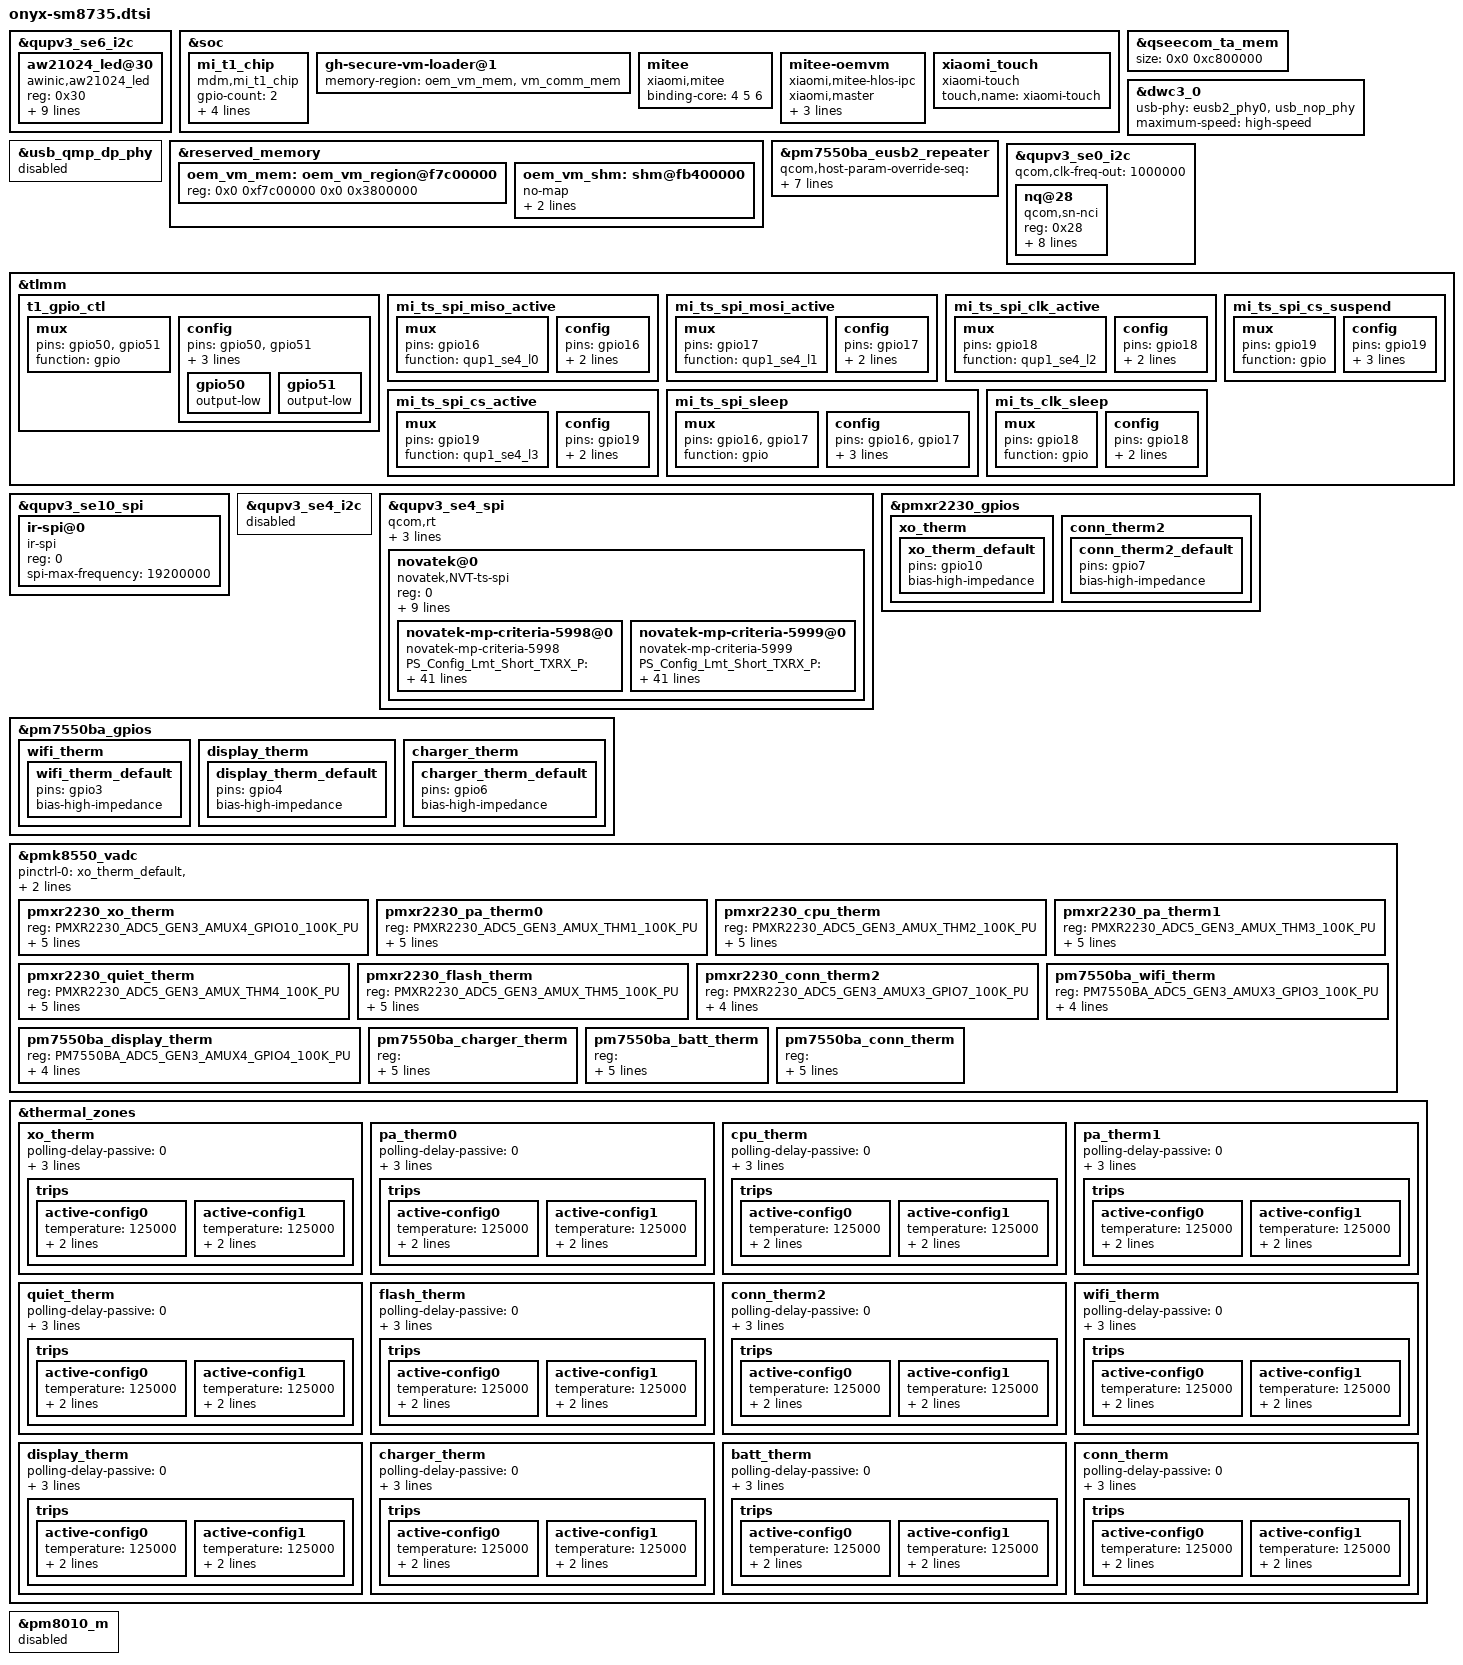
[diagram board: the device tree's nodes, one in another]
/*
  this file is for attribution only of onyx
  And public attribution of xiaomi platforms（like O10U and so on)
*/

#include "onyx-pinctrl.dtsi"
#include "sm8735-xiaomi-common.dtsi"
#include "onyx-charger-common.dtsi"
#include "onyx-sm8735-xiaomi-fingerprint.dtsi"
#include <dt-bindings/iio/qcom,spmi-adc5-gen3-pm7550ba.h>
#include <dt-bindings/iio/qcom,spmi-adc5-gen3-pmxr2230.h>


&qupv3_se6_i2c {
  status = "ok";
  aw21024_led@30 {
		compatible = "awinic,aw21024_led";
		reg = <0x30>;
		reset-gpio = <&tlmm 148 0>;
		apse_mode;
		/* 0:16M 1:8M 2:1M 3:512K 4:256K 5:125K 6:62K 7:31K */
		clk_pwm = <1>;
		/* 255 1023 2047 */
		max_brightness = <255>;
		led_current = <127>;
		led_wbr = <255>;
		led_wbg = <200>;
		led_wbb = <175>;
		brightness = <125>;
		status = "ok";
	};
};

&soc {
	mi_t1_chip {
		compatible = "mdm,mi_t1_chip";
		gpio-count = <2>;
		first-gpio = <50>;
		mi-t1-gpio-1 = <&tlmm 50 0x0>;
		mi-t1-gpio-2 = <&tlmm 51 0x0>;
		    pinctrl-0 = <&t1_gpio_ctl>;
	};
};

&qseecom_ta_mem {
		size = <0x0 0xc800000>;
};

&dwc3_0 {
	usb-phy = <&eusb2_phy0>, <&usb_nop_phy>;
	maximum-speed = "high-speed";
};

&usb_qmp_dp_phy {
	status = "disabled";
};

/* mitee vm */
&reserved_memory {
	oem_vm_mem: oem_vm_region@f7c00000 {
		reg = <0x0 0xf7c00000 0x0 0x3800000>;
	};

	oem_vm_shm: shm@fb400000 {
		no-map;
		reg = <0x0 0xfb400000 0x0 0x400000>;
		gunyah-label = <0x3>;
	};
};

&soc {
	gh-secure-vm-loader@1 {
		memory-region = <&oem_vm_mem &vm_comm_mem>;
	};

	mitee: mitee {
		compatible = "xiaomi,mitee";
		binding-core = <4 5 6>;
	};

	mitee-oemvm {
		compatible = "xiaomi,mitee-hlos-ipc";
		xiaomi,master;
		gunyah-shm-label = <0x3>;
		peer-name = <0x4>;
		shared-buffer = <&oem_vm_shm>;
	};
};
/* mitee vm */

&pm7550ba_eusb2_repeater {
	qcom,host-param-override-seq =
		<0x00 0x50
		0x0c 0x51
		0x03 0x52
		0x07 0x53
		0x01 0x54
		0x01 0x55
		0x00 0x56
		0x06 0x57
		0x02 0x58
		0x00 0x59
		0x03 0x5a
		0x02 0x5b>;
	qcom,param-override-seq-factory =
		<0x00 0x50
		0x0F 0x51
		0x05 0x52
		0x07 0x53
		0x01 0x54
		0x01 0x55
		0x00 0x56
		0x06 0x57
		0x02 0x58
		0x00 0x59
		0x03 0x5a
		0x02 0x5b>;
	qcom,param-override-seq =
		<0x00 0x50
		0x0E 0x51
		0x01 0x52
		0x07 0x53
		0x01 0x54
		0x03 0x55
		0x00 0x56
		0x07 0x57
		0x02 0x58
		0x03 0x59
		0x01 0x5a
		0x02 0x5b>;
	qcom,param-override-seq-host-ms =
		<0x00 0x50
		0x0c 0x51
		0x03 0x52
		0x07 0x53
		0x01 0x54
		0x01 0x55
		0x00 0x56
		0x06 0x57
		0x02 0x58
		0x00 0x59
		0x03 0x5a
		0x02 0x5b>;
};

&qupv3_se0_i2c {
	status = "ok";
	qcom,clk-freq-out = <1000000>;
	#address-cells = <1>;
	#size-cells = <0>;
	nq@28 {
		compatible = "qcom,sn-nci";
		reg = <0x28>;
		qcom,sn-irq = <&tlmm 55 0x00>;
		qcom,sn-ven = <&tlmm 114 0x00>;
		qcom,sn-clkreq = <&tlmm 115 0x00>;
		qcom,sn-szone = "enable";
		interrupt-parent = <&tlmm>;
		interrupts = <55 0>;
		interrupt-names = "nfc_irq";
		pinctrl-names = "nfc_active", "nfc_suspend";
		pinctrl-0 = <&nfc_int_active &nfc_enable_active>;
		pinctrl-1 = <&nfc_int_suspend &nfc_enable_suspend>;
	};
};

&tlmm {
	/*t1s gpio config*/
	t1_gpio_ctl: t1_gpio_ctl {
		mux {
			pins = "gpio50", "gpio51";
			function = "gpio";
		};
		config {
			pins = "gpio50", "gpio51";
			drive-strength = <2>;
			bias-disable;
			output-enable;
			gpio50 {
			output-low;
			};
			gpio51 {
			output-low;
			};
		};
	};
};

&qupv3_se10_spi {
	status = "ok";
	ir-spi@0 {
		compatible = "ir-spi";
		reg = <0>;
		spi-max-frequency = <19200000>;
		status = "ok";
	};
};

&soc {
	xiaomi_touch {
		compatible = "xiaomi-touch";
		status = "ok";
		touch,name = "xiaomi-touch";
	};
};

&qupv3_se4_i2c {
	status = "disable";
};

&tlmm {
	mi_ts_spi_miso_active: mi_ts_spi_miso_active {
		mux {
			pins = "gpio16";
			function = "qup1_se4_l0";
		};
		config {
			pins = "gpio16";
			drive-strength = <6>;
			bias-disable;
		};
	};
	mi_ts_spi_mosi_active: mi_ts_spi_mosi_active {
		mux {
			pins = "gpio17";
			function = "qup1_se4_l1";
		};
		config {
			pins = "gpio17";
			drive-strength = <6>;
			bias-disable;
		};
	};
	mi_ts_spi_clk_active: mi_ts_spi_clk_active {
		mux {
			pins = "gpio18";
			function = "qup1_se4_l2";
		};
		config {
			pins = "gpio18";
			drive-strength = <6>;
			bias-disable;
		};
	};
	mi_ts_spi_cs_active: mi_ts_spi_cs_active {
		mux {
			pins = "gpio19";
			function = "qup1_se4_l3";
		};
		config {
			pins = "gpio19";
			drive-strength = <6>;
			bias-disable;
		};
	};
	mi_ts_spi_cs_suspend: mi_ts_spi_cs_suspend {
		mux {
			pins = "gpio19";
			function = "gpio";
		};
		config {
			pins = "gpio19";
			drive-strength = <2>;
			bias-pull-down;
			output-low;
		};
	};
	mi_ts_spi_sleep: mi_ts_spi_sleep {
		mux {
			pins = "gpio16", "gpio17";
			function = "gpio";
		};
		config {
			pins = "gpio16", "gpio17";
			drive-strength = <2>;
			output-low;
			bias-disable;
		};
	};
	mi_ts_clk_sleep: mi_ts_clk_sleep {
		mux {
			pins = "gpio18";
			function = "gpio";
		};
		config {
			pins = "gpio18";
			drive-strength = <2>;
			bias-pull-down;
		};
	};
};

&qupv3_se4_spi {
	status = "ok";
	qcom,rt;
	pinctrl-0 = <&mi_ts_spi_mosi_active>, <&mi_ts_spi_miso_active>,
				<&mi_ts_spi_clk_active>;
	pinctrl-1 = <&mi_ts_spi_sleep>, <&mi_ts_clk_sleep>;
	//qcom,la-vm;
	/* Novatek device tree node */
	novatek@0 {
		compatible = "novatek,NVT-ts-spi";
		reg = <0>; //Same as CS ID
		status = "ok";
		spi-max-frequency = <19200000>;	//4800000,9600000,15000000,19200000
		
		novatek,irq-gpio = <&tlmm 78 0x2008>;
		//novatek,reset-gpio = <&tlmm 14 0x00>;
		novatek,lcd_id-gpio1 = <&tlmm 27 0x00>;
		novatek,lcd_id-gpio2 = <&tlmm 46 0x00>;
		spi-cs-setup-delay-ns = <300>;
		spi-cs-hold-delay-ns = <300>;
		pinctrl-0 = <&mi_ts_spi_cs_active>;
		pinctrl-1 = <&mi_ts_spi_cs_suspend>;
		pinctrl-names = "pmx_ts_active", "pmx_ts_suspend";
		/* MP */
		novatek,mp-support-dt;
		/* for Xiaomi O10U NT38771 CSOT6.83" panel module */
		novatek-mp-criteria-5998@0 {
			#address-cells = <1>;
			#size-cells = <0>;
			compatible = "novatek-mp-criteria-5998";

			/* MP Criteria */
			PS_Config_Lmt_Short_TXRX_P = <
				3500 3500 3500 3500 3500 3500 3500 3500 3500 3500 3500 3500 3500 3500 3500 3500 3500 3500
				3500 3500 3500 3500 3500 3500 3500 3500 3500 3500 3500 3500 3500 3500 3500 3500 3500 3500
				3500 3500 3500 3500 3500 3500 3500 3500 3500 3500 3500 3500 3500 3500 3500 3500 3500 3500
				3500 3500 3500 3500 3500 3500 3500 3500 3500 3500 3500 3500 3500 3500 3500 3500 3500 3500
				3500 3500 3500 3500 3500 3500 3500 3500 3500 3500 3500 3500 3500 3500 3500 3500 3500 3500
				3500 3500 3500 3500 3500 3500 3500 3500 3500 3500 3500 3500 3500 3500 3500 3500 3500 3500
				3500 3500 3500 3500 3500 3500 3500 3500 3500 3500 3500 3500 3500 3500 3500 3500 3500 3500
				3500 3500 3500 3500 3500 3500 3500 3500 3500 3500 3500 3500 3500 3500 3500 3500 3500 3500
				3500 3500 3500 3500 3500 3500 3500 3500 3500 3500 3500 3500 3500 3500 3500 3500 3500 3500
				3500 3500 3500 3500 3500 3500 3500 3500 3500 3500 3500 3500 3500 3500 3500 3500 3500 3500
				3500 3500 3500 3500 3500 3500 3500 3500 3500 3500 3500 3500 3500 3500 3500 3500 3500 3500
				3500 3500 3500 3500 3500 3500 3500 3500 3500 3500 3500 3500 3500 3500 3500 3500 3500 3500
				3500 3500 3500 3500 3500 3500 3500 3500 3500 3500 3500 3500 3500 3500 3500 3500 3500 3500
				3500 3500 3500 3500 3500 3500 3500 3500 3500 3500 3500 3500 3500 3500 3500 3500 3500 3500
				3500 3500 3500 3500 3500 3500 3500 3500 3500 3500 3500 3500 3500 3500 3500 3500 3500 3500
				3500 3500 3500 3500 3500 3500 3500 3500 3500 3500 3500 3500 3500 3500 3500 3500 3500 3500
				3500 3500 3500 3500 3500 3500 3500 3500 3500 3500 3500 3500 3500 3500 3500 3500 3500 3500
				3500 3500 3500 3500 3500 3500 3500 3500 3500 3500 3500 3500 3500 3500 3500 3500 3500 3500
				3500 3500 3500 3500 3500 3500 3500 3500 3500 3500 3500 3500 3500 3500 3500 3500 3500 3500
				3500 3500 3500 3500 3500 3500 3500 3500 3500 3500 3500 3500 3500 3500 3500 3500 3500 3500
				3500 3500 3500 3500 3500 3500 3500 3500 3500 3500 3500 3500 3500 3500 3500 3500 3500 3500
				3500 3500 3500 3500 3500 3500 3500 3500 3500 3500 3500 3500 3500 3500 3500 3500 3500 3500
				3500 3500 3500 3500 3500 3500 3500 3500 3500 3500 3500 3500 3500 3500 3500 3500 3500 3500
				3500 3500 3500 3500 3500 3500 3500 3500 3500 3500 3500 3500 3500 3500 3500 3500 3500 3500
				3500 3500 3500 3500 3500 3500 3500 3500 3500 3500 3500 3500 3500 3500 3500 3500 3500 3500
				3500 3500 3500 3500 3500 3500 3500 3500 3500 3500 3500 3500 3500 3500 3500 3500 3500 3500
				3500 3500 3500 3500 3500 3500 3500 3500 3500 3500 3500 3500 3500 3500 3500 3500 3500 3500
				3500 3500 3500 3500 3500 3500 3500 3500 3500 3500 3500 3500 3500 3500 3500 3500 3500 3500
				3500 3500 3500 3500 3500 3500 3500 3500 3500 3500 3500 3500 3500 3500 3500 3500 3500 3500
				3500 3500 3500 3500 3500 3500 3500 3500 3500 3500 3500 3500 3500 3500 3500 3500 3500 3500
				3500 3500 3500 3500 3500 3500 3500 3500 3500 3500 3500 3500 3500 3500 3500 3500 3500 3500
				3500 3500 3500 3500 3500 3500 3500 3500 3500 3500 3500 3500 3500 3500 3500 3500 3500 3500
				3500 3500 3500 3500 3500 3500 3500 3500 3500 3500 3500 3500 3500 3500 3500 3500 3500 3500
				3500 3500 3500 3500 3500 3500 3500 3500 3500 3500 3500 3500 3500 3500 3500 3500 3500 3500
				3500 3500 3500 3500 3500 3500 3500 3500 3500 3500 3500 3500 3500 3500 3500 3500 3500 3500
				3500 3500 3500 3500 3500 3500 3500 3500 3500 3500 3500 3500 3500 3500 3500 3500 3500 3500
				3500 3500 3500 3500 3500 3500 3500 3500 3500 3500 3500 3500 3500 3500 3500 3500 3500 3500
				3500 3500 3500 3500 3500 3500 3500 3500 3500 3500 3500 3500 3500 3500 3500 3500 3500 3500
				3500 3500 3500 3500 3500 3500 3500 3500 3500 3500 3500 3500 3500 3500 3500 3500 3500 3500
				>;

			PS_Config_Lmt_Short_TXRX_N = <
				1900 1900 1900 1900 1900 1900 1900 1900 1900 1900 1900 1900 1900 1900 1900 1900 1900 1900
				1900 1900 1900 1900 1900 1900 1900 1900 1900 1900 1900 1900 1900 1900 1900 1900 1900 1900
				1900 1900 1900 1900 1900 1900 1900 1900 1900 1900 1900 1900 1900 1900 1900 1900 1900 1900
				1900 1900 1900 1900 1900 1900 1900 1900 1900 1900 1900 1900 1900 1900 1900 1900 1900 1900
				1900 1900 1900 1900 1900 1900 1900 1900 1900 1900 1900 1900 1900 1900 1900 1900 1900 1900
				1900 1900 1900 1900 1900 1900 1900 1900 1900 1900 1900 1900 1900 1900 1900 1900 1900 1900
				1900 1900 1900 1900 1900 1900 1900 1900 1900 1900 1900 1900 1900 1900 1900 1900 1900 1900
				1900 1900 1900 1900 1900 1900 1900 1900 1900 1900 1900 1900 1900 1900 1900 1900 1900 1900
				1900 1900 1900 1900 1900 1900 1900 1900 1900 1900 1900 1900 1900 1900 1900 1900 1900 1900
				1900 1900 1900 1900 1900 1900 1900 1900 1900 1900 1900 1900 1900 1900 1900 1900 1900 1900
				1900 1900 1900 1900 1900 1900 1900 1900 1900 1900 1900 1900 1900 1900 1900 1900 1900 1900
				1900 1900 1900 1900 1900 1900 1900 1900 1900 1900 1900 1900 1900 1900 1900 1900 1900 1900
				1900 1900 1900 1900 1900 1900 1900 1900 1900 1900 1900 1900 1900 1900 1900 1900 1900 1900
				1900 1900 1900 1900 1900 1900 1900 1900 1900 1900 1900 1900 1900 1900 1900 1900 1900 1900
				1900 1900 1900 1900 1900 1900 1900 1900 1900 1900 1900 1900 1900 1900 1900 1900 1900 1900
				1900 1900 1900 1900 1900 1900 1900 1900 1900 1900 1900 1900 1900 1900 1900 1900 1900 1900
				1900 1900 1900 1900 1900 1900 1900 1900 1900 1900 1900 1900 1900 1900 1900 1900 1900 1900
				1900 1900 1900 1900 1900 1900 1900 1900 1900 1900 1900 1900 1900 1900 1900 1900 1900 1900
				1900 1900 1900 1900 1900 1900 1900 1900 1900 1900 1900 1900 1900 1900 1900 1900 1900 1900
				1900 1900 1900 1900 1900 1900 1900 1900 1900 1900 1900 1900 1900 1900 1900 1900 1900 1900
				1900 1900 1900 1900 1900 1900 1900 1900 1900 1900 1900 1900 1900 1900 1900 1900 1900 1900
				1900 1900 1900 1900 1900 1900 1900 1900 1900 1900 1900 1900 1900 1900 1900 1900 1900 1900
				1900 1900 1900 1900 1900 1900 1900 1900 1900 1900 1900 1900 1900 1900 1900 1900 1900 1900
				1900 1900 1900 1900 1900 1900 1900 1900 1900 1900 1900 1900 1900 1900 1900 1900 1900 1900
				1900 1900 1900 1900 1900 1900 1900 1900 1900 1900 1900 1900 1900 1900 1900 1900 1900 1900
				1900 1900 1900 1900 1900 1900 1900 1900 1900 1900 1900 1900 1900 1900 1900 1900 1900 1900
				1900 1900 1900 1900 1900 1900 1900 1900 1900 1900 1900 1900 1900 1900 1900 1900 1900 1900
				1900 1900 1900 1900 1900 1900 1900 1900 1900 1900 1900 1900 1900 1900 1900 1900 1900 1900
				1900 1900 1900 1900 1900 1900 1900 1900 1900 1900 1900 1900 1900 1900 1900 1900 1900 1900
				1900 1900 1900 1900 1900 1900 1900 1900 1900 1900 1900 1900 1900 1900 1900 1900 1900 1900
				1900 1900 1900 1900 1900 1900 1900 1900 1900 1900 1900 1900 1900 1900 1900 1900 1900 1900
				1900 1900 1900 1900 1900 1900 1900 1900 1900 1900 1900 1900 1900 1900 1900 1900 1900 1900
				1900 1900 1900 1900 1900 1900 1900 1900 1900 1900 1900 1900 1900 1900 1900 1900 1900 1900
				1900 1900 1900 1900 1900 1900 1900 1900 1900 1900 1900 1900 1900 1900 1900 1900 1900 1900
				1900 1900 1900 1900 1900 1900 1900 1900 1900 1900 1900 1900 1900 1900 1900 1900 1900 1900
				1900 1900 1900 1900 1900 1900 1900 1900 1900 1900 1900 1900 1900 1900 1900 1900 1900 1900
				1900 1900 1900 1900 1900 1900 1900 1900 1900 1900 1900 1900 1900 1900 1900 1900 1900 1900
				1900 1900 1900 1900 1900 1900 1900 1900 1900 1900 1900 1900 1900 1900 1900 1900 1900 1900
				1900 1900 1900 1900 1900 1900 1900 1900 1900 1900 1900 1900 1900 1900 1900 1900 1900 1900
				>;

			PS_Config_Lmt_Short_TXTX_P = <
				3500 3500 3500 3500 3500 3500 3500 3500 3500 3500 3500 3500 3500 3500 3500 3500 3500 3500
				>;

			PS_Config_Lmt_Short_TXTX_N = <
				1900 1900 1900 1900 1900 1900 1900 1900 1900 1900 1900 1900 1900 1900 1900 1900 1900 1900
				>;

			PS_Config_Lmt_Short_RXRX_P = <
				3500
				3500
				3500
				3500
				3500
				3500
				3500
				3500
				3500
				3500
				3500
				3500
				3500
				3500
				3500
				3500
				3500
				3500
				3500
				3500
				3500
				3500
				3500
				3500
				3500
				3500
				3500
				3500
				3500
				3500
				3500
				3500
				3500
				3500
				3500
				3500
				3500
				3500
				3500
				>;

			PS_Config_Lmt_Short_RXRX_N = <
				1900
				1900
				1900
				1900
				1900
				1900
				1900
				1900
				1900
				1900
				1900
				1900
				1900
				1900
				1900
				1900
				1900
				1900
				1900
				1900
				1900
				1900
				1900
				1900
				1900
				1900
				1900
				1900
				1900
				1900
				1900
				1900
				1900
				1900
				1900
				1900
				1900
				1900
				1900
				>;

			PS_Config_Lmt_Open_Mutual_P = <
				65535 4000 4000 4000 4000 4000 4000 4000 4000 4000 4000 4000 4000 4000 4000 4000 4000 65535
				4000 4000 4000 4000 4000 4000 4000 4000 4000 4000 4000 4000 4000 4000 4000 4000 4000 4000
				4000 4000 4000 4000 4000 4000 4000 4000 4000 4000 4000 4000 4000 4000 4000 4000 4000 4000
				4000 4000 4000 4000 4000 4000 4000 4000 4000 4000 4000 4000 4000 4000 4000 4000 4000 4000
				4000 4000 4000 4000 4000 4000 4000 4000 4000 4000 4000 4000 4000 4000 4000 4000 4000 4000
				4000 4000 4000 4000 4000 4000 4000 4000 4000 4000 4000 4000 4000 4000 4000 4000 4000 4000
				4000 4000 4000 4000 4000 4000 4000 4000 4000 4000 4000 4000 4000 4000 4000 4000 4000 4000
				4000 4000 4000 4000 4000 4000 4000 4000 4000 4000 4000 4000 4000 4000 4000 4000 4000 4000
				4000 4000 4000 4000 4000 4000 4000 4000 4000 4000 4000 4000 4000 4000 4000 4000 4000 4000
				4000 4000 4000 4000 4000 4000 4000 4000 4000 4000 4000 4000 4000 4000 4000 4000 4000 4000
				4000 4000 4000 4000 4000 4000 4000 4000 4000 4000 4000 4000 4000 4000 4000 4000 4000 4000
				4000 4000 4000 4000 4000 4000 4000 4000 4000 4000 4000 4000 4000 4000 4000 4000 4000 4000
				4000 4000 4000 4000 4000 4000 4000 4000 4000 4000 4000 4000 4000 4000 4000 4000 4000 4000
				4000 4000 4000 4000 4000 4000 4000 4000 4000 4000 4000 4000 4000 4000 4000 4000 4000 4000
				4000 4000 4000 4000 4000 4000 4000 4000 4000 4000 4000 4000 4000 4000 4000 4000 4000 4000
				4000 4000 4000 4000 4000 4000 4000 4000 4000 4000 4000 4000 4000 4000 4000 4000 4000 4000
				4000 4000 4000 4000 4000 4000 4000 4000 4000 4000 4000 4000 4000 4000 4000 4000 4000 4000
				4000 4000 4000 4000 4000 4000 4000 4000 4000 4000 4000 4000 4000 4000 4000 4000 4000 4000
				4000 4000 4000 4000 4000 4000 4000 4000 4000 4000 4000 4000 4000 4000 4000 4000 4000 4000
				4000 4000 4000 4000 4000 4000 4000 4000 4000 4000 4000 4000 4000 4000 4000 4000 4000 4000
				4000 4000 4000 4000 4000 4000 4000 4000 4000 4000 4000 4000 4000 4000 4000 4000 4000 4000
				4000 4000 4000 4000 4000 4000 4000 4000 4000 4000 4000 4000 4000 4000 4000 4000 4000 4000
				4000 4000 4000 4000 4000 4000 4000 4000 4000 4000 4000 4000 4000 4000 4000 4000 4000 4000
				4000 4000 4000 4000 4000 4000 4000 4000 4000 4000 4000 4000 4000 4000 4000 4000 4000 4000
				4000 4000 4000 4000 4000 4000 4000 4000 4000 4000 4000 4000 4000 4000 4000 4000 4000 4000
				4000 4000 4000 4000 4000 4000 4000 4000 4000 4000 4000 4000 4000 4000 4000 4000 4000 4000
				4000 4000 4000 4000 4000 4000 4000 4000 4000 4000 4000 4000 4000 4000 4000 4000 4000 4000
				4000 4000 4000 4000 4000 4000 4000 4000 4000 4000 4000 4000 4000 4000 4000 4000 4000 4000
				4000 4000 4000 4000 4000 4000 4000 4000 4000 4000 4000 4000 4000 4000 4000 4000 4000 4000
				4000 4000 4000 4000 4000 4000 4000 4000 4000 4000 4000 4000 4000 4000 4000 4000 4000 4000
				4000 4000 4000 4000 4000 4000 4000 4000 4000 4000 4000 4000 4000 4000 4000 4000 4000 4000
				4000 4000 4000 4000 4000 4000 4000 4000 4000 4000 4000 4000 4000 4000 4000 4000 4000 4000
				4000 4000 4000 4000 4000 4000 4000 4000 4000 4000 4000 4000 4000 4000 4000 4000 4000 4000
				4000 4000 4000 4000 4000 4000 4000 4000 4000 4000 4000 4000 4000 4000 4000 4000 4000 4000
				4000 4000 4000 4000 4000 4000 4000 4000 4000 4000 4000 4000 4000 4000 4000 4000 4000 4000
				4000 4000 4000 4000 4000 4000 4000 4000 4000 4000 4000 4000 4000 4000 4000 4000 4000 4000
				4000 4000 4000 4000 4000 4000 4000 4000 4000 4000 4000 4000 4000 4000 4000 4000 4000 4000
				4000 4000 4000 4000 4000 4000 4000 4000 4000 4000 4000 4000 4000 4000 4000 4000 4000 4000
				65535 4000 4000 4000 4000 4000 4000 4000 4000 4000 4000 4000 4000 4000 4000 4000 4000 65535
				>;

			PS_Config_Lmt_Open_Mutual_N = <
				(-65535) 973 976 973 977 973 976 972 900 891 962 965 958 960 955 952 902 (-65535)
				995	987	972	968	973	968	973	969	743	736	958	961	953	956	950	949	951	899
				1038	991	976	973	976	971	976	972	979	971	961	964	957	959	953	953	953	957
				1007	997	986	958	962	958	963	958	962	953	946	950	943	946	940	938	939	943
				995	998	980	956	959	955	960	955	958	949	943	947	940	943	937	935	936	938
				997	994	976	952	956	952	958	952	956	947	940	944	938	939	932	932	932	935
				989	994	980	955	957	953	958	953	956	947	941	944	938	940	934	933	933	935
				983	962	949	965	973	946	950	945	949	939	932	937	930	932	925	925	925	928
				992	976	960	982	983	958	962	956	960	951	944	948	943	944	938	938	937	939
				976	957	943	965	964	942	946	941	945	935	928	933	925	928	922	920	920	922
				983	967	954	973	976	951	955	950	953	944	937	941	935	937	930	931	930	932
				976	957	944	939	944	961	969	941	945	935	928	932	925	926	920	920	920	921
				984	969	955	950	954	974	976	951	955	945	938	943	935	938	932	931	931	932
				978	957	944	939	944	965	965	941	946	936	929	932	926	928	921	920	920	923
				985	968	953	947	949	968	974	947	952	943	935	939	933	934	928	928	928	929
				988	962	948	942	946	942	947	964	973	939	932	936	928	930	924	922	923	925
				1004 974 958 950 952 947 952 972 974 944 938 941 935 936 930 929 929 931
				1017 968 950 941 943 938 944 965 967 935 929 933 926 928 922 920 920 922
				1109 1001 976 957 952 947 952 970 975 944 938 943 935 937 931 929 930 932
				946	952	940	937	944	941	947	943	947	959	953	958	953	955	950	950	951	991
				946	950	939	937	944	941	946	941	946	958	952	958	953	955	950	950	950	991
				937	944	932	929	937	934	940	935	940	951	946	951	946	949	945	944	946	980
				932	938	927	924	932	929	934	930	935	946	940	945	940	943	940	938	940	980
				940	946	935	932	940	937	942	938	943	954	948	953	948	951	949	972	970	964
				930	935	925	922	930	927	932	928	933	943	938	943	938	941	938	959	964	955
				938	944	932	930	937	934	940	936	940	951	946	950	946	949	947	967	974	962
				925	929	919	916	923	920	926	922	926	937	931	936	931	934	931	955	958	947
				926	931	920	917	925	922	927	922	927	938	933	938	932	959	953	934	937	952
				926	930	921	918	926	922	928	923	928	939	934	939	933	957	957	934	937	951
				923	926	917	915	922	919	924	920	925	935	930	935	930	952	956	932	935	949
				917	921	912	909	917	914	919	914	919	930	925	930	924	950	947	925	929	943
				918	922	912	910	917	914	919	915	920	931	925	953	945	928	926	927	931	947
				919	920	913	910	917	914	920	915	920	931	926	951	949	928	925	926	931	945
				922	925	917	913	921	918	923	919	923	934	929	953	953	932	931	932	937	953
				912	916	908	904	912	908	914	910	914	926	920	948	942	923	922	922	928	942
				920	923	915	912	920	917	922	918	922	957	949	933	928	931	931	933	941	958
				913	916	910	907	914	911	916	912	917	949	945	927	921	924	923	925	933	950
				877	927	922	917	925	922	928	923	928	962	959	938	933	937	938	955	962	938
				(-65535) 829 920 919 925 916 929 926 934 967 959 938 929 934 942 946 890 (-65535)
				>;

			PS_Config_Lmt_Open_SelfTX_P = <
				4000 4000 4000 4000 4000 4000 4000 4000 4000 4000 4000 4000 4000 4000 4000 4000 4000 4000
				>;

			PS_Config_Lmt_Open_SelfTX_N = <
				1365 1385 1394 1391 1401 1379 1385 1386 1384 1376 1376 1379 1363 1388 1375 1377 1369 1354
				>;

			PS_Config_Lmt_Open_SelfRX_P = <
				4000
				4000
				4000
				4000
				4000
				4000
				4000
				4000
				4000
				4000
				4000
				4000
				4000
				4000
				4000
				4000
				4000
				4000
				4000
				4000
				4000
				4000
				4000
				4000
				4000
				4000
				4000
				4000
				4000
				4000
				4000
				4000
				4000
				4000
				4000
				4000
				4000
				4000
				4000
				>;

			PS_Config_Lmt_Open_SelfRX_N = <
				816
				833
				846
				857
				850
				863
				851
				851
				851
				848
				844
				844
				838
				840
				838
				837
				832
				831
				830
				823
				832
				820
				830
				820
				820
				826
				826
				824
				824
				820
				821
				821
				818
				820
				817
				822
				807
				787
				747
				>;

			PS_Config_Lmt_FW_Rawdata_P = <
				2867	2870	2867	2866	2866	2869	2866	2867	2867	2866	2867	2867	2869	2866	2867	2867	2869	2867
				2869	2870	2867	2866	2867	2869	2867	2869	2867	2866	2869	2869	2869	2866	2867	2867	2870	2869
				2867	2870	2866	2866	2866	2869	2866	2869	2869	2866	2869	2869	2869	2866	2867	2867	2869	2869
				2869	2871	2869	2867	2867	2870	2867	2870	2869	2867	2870	2869	2870	2867	2869	2869	2870	2870
				2867	2870	2866	2866	2866	2869	2866	2867	2869	2866	2869	2867	2869	2866	2867	2867	2869	2869
				2869	2871	2869	2867	2869	2870	2867	2870	2870	2867	2870	2870	2870	2867	2869	2869	2871	2871
				2867	2870	2866	2866	2866	2867	2866	2869	2869	2866	2867	2867	2869	2866	2867	2867	2869	2869
				2869	2871	2867	2867	2867	2869	2867	2869	2869	2867	2869	2869	2870	2867	2869	2867	2870	2870
				2869	2871	2866	2867	2867	2869	2866	2869	2869	2866	2869	2869	2870	2866	2867	2867	2870	2870
				2869	2871	2867	2867	2867	2869	2867	2869	2869	2867	2869	2869	2870	2867	2869	2869	2870	2870
				2867	2870	2866	2867	2866	2869	2866	2869	2869	2866	2869	2869	2870	2866	2867	2867	2870	2869
				2869	2871	2867	2867	2867	2869	2867	2869	2869	2867	2869	2869	2870	2867	2867	2867	2870	2870
				2869	2871	2867	2866	2867	2869	2867	2869	2869	2867	2869	2869	2870	2867	2869	2867	2870	2870
				2869	2871	2869	2869	2869	2870	2867	2870	2870	2867	2869	2870	2870	2869	2869	2869	2871	2871
				2869	2871	2867	2866	2867	2869	2866	2869	2869	2866	2869	2867	2870	2867	2867	2867	2870	2870
				2870	2873	2869	2869	2869	2870	2869	2870	2870	2869	2870	2870	2871	2869	2869	2870	2871	2871
				2869	2870	2867	2867	2867	2869	2866	2869	2869	2866	2869	2869	2869	2866	2867	2867	2869	2869
				2869	2871	2869	2869	2867	2870	2867	2870	2870	2869	2870	2870	2870	2869	2869	2869	2870	2870
				2869	2871	2867	2867	2867	2870	2867	2869	2869	2867	2869	2869	2870	2867	2869	2867	2870	2870
				2867	2870	2867	2867	2866	2869	2866	2869	2869	2866	2869	2867	2869	2866	2869	2867	2869	2869
				2869	2870	2867	2867	2867	2870	2867	2869	2869	2867	2869	2867	2870	2867	2869	2869	2870	2870
				2867	2869	2866	2866	2866	2869	2866	2869	2867	2866	2867	2866	2869	2866	2869	2866	2869	2869
				2869	2870	2867	2867	2867	2870	2867	2869	2869	2867	2869	2867	2870	2867	2869	2869	2870	2870
				2867	2869	2866	2866	2866	2869	2867	2869	2869	2866	2869	2867	2869	2866	2869	2867	2869	2869
				2867	2870	2867	2867	2866	2870	2867	2869	2867	2867	2869	2867	2869	2866	2869	2867	2870	2869
				2869	2870	2867	2867	2867	2870	2867	2869	2869	2867	2869	2867	2870	2866	2869	2867	2870	2870
				2869	2870	2867	2867	2867	2870	2867	2869	2869	2867	2869	2867	2870	2866	2869	2867	2869	2869
				2867	2869	2867	2867	2866	2870	2866	2869	2867	2866	2869	2867	2869	2866	2869	2867	2869	2869
				2869	2871	2867	2869	2867	2871	2869	2870	2870	2869	2870	2869	2870	2867	2870	2869	2870	2870
				2867	2869	2867	2866	2866	2870	2866	2869	2867	2866	2869	2867	2869	2866	2867	2867	2869	2869
				2869	2870	2867	2867	2867	2870	2867	2869	2869	2867	2869	2869	2870	2867	2869	2869	2870	2870
				2867	2870	2867	2866	2866	2870	2866	2869	2867	2867	2869	2867	2869	2866	2869	2867	2869	2869
				2869	2871	2869	2867	2867	2871	2869	2870	2869	2869	2870	2869	2870	2867	2870	2869	2870	2870
				2869	2870	2867	2867	2867	2870	2867	2869	2869	2867	2869	2867	2869	2866	2869	2867	2869	2869
				2869	2870	2867	2867	2867	2870	2867	2869	2869	2867	2869	2867	2870	2866	2869	2867	2870	2869
				2869	2870	2867	2867	2867	2870	2866	2869	2869	2867	2869	2867	2869	2866	2869	2869	2870	2869
				2867	2870	2867	2866	2866	2869	2866	2867	2867	2866	2867	2866	2867	2866	2869	2867	2870	2869
				2867	2869	2866	2866	2864	2866	2863	2866	2864	2864	2866	2864	2866	2864	2867	2867	2869	2869
				2867	2869	2866	2864	2863	2866	2863	2864	2863	2863	2864	2863	2864	2863	2866	2864	2869	2867
				>;

			PS_Config_Lmt_FW_Rawdata_N = <
				1229	1230	1229	1228	1228	1229	1228	1229	1229	1228	1229	1229	1229	1228	1229	1229	1229	1229
				1229	1230	1229	1228	1229	1229	1229	1229	1229	1228	1229	1229	1229	1228	1229	1229	1230	1229
				1229	1230	1228	1228	1228	1229	1228	1229	1229	1228	1229	1229	1229	1228	1229	1229	1229	1229
				1229	1231	1229	1229	1229	1230	1229	1230	1229	1229	1230	1229	1230	1229	1229	1229	1230	1230
				1229	1230	1228	1228	1228	1229	1228	1229	1229	1228	1229	1229	1229	1228	1229	1229	1229	1229
				1229	1231	1229	1229	1229	1230	1229	1230	1230	1229	1230	1230	1230	1229	1229	1229	1231	1231
				1229	1230	1228	1228	1228	1229	1228	1229	1229	1228	1229	1229	1229	1228	1229	1229	1229	1229
				1229	1231	1229	1229	1229	1229	1229	1229	1229	1229	1229	1229	1230	1229	1229	1229	1230	1230
				1229	1231	1228	1229	1229	1229	1228	1229	1229	1228	1229	1229	1230	1228	1229	1229	1230	1230
				1229	1231	1229	1229	1229	1229	1229	1229	1229	1229	1229	1229	1230	1229	1229	1229	1230	1230
				1229	1230	1228	1229	1228	1229	1228	1229	1229	1228	1229	1229	1230	1228	1229	1229	1230	1229
				1229	1231	1229	1229	1229	1229	1229	1229	1229	1229	1229	1229	1230	1229	1229	1229	1230	1230
				1229	1231	1229	1228	1229	1229	1229	1229	1229	1229	1229	1229	1230	1229	1229	1229	1230	1230
				1229	1231	1229	1229	1229	1230	1229	1230	1230	1229	1229	1230	1230	1229	1229	1229	1231	1231
				1229	1231	1229	1228	1229	1229	1228	1229	1229	1228	1229	1229	1230	1229	1229	1229	1230	1230
				1230	1231	1229	1229	1229	1230	1229	1230	1230	1229	1230	1230	1231	1229	1229	1230	1231	1231
				1229	1230	1229	1229	1229	1229	1228	1229	1229	1228	1229	1229	1229	1228	1229	1229	1229	1229
				1229	1231	1229	1229	1229	1230	1229	1230	1230	1229	1230	1230	1230	1229	1229	1229	1230	1230
				1229	1231	1229	1229	1229	1230	1229	1229	1229	1229	1229	1229	1230	1229	1229	1229	1230	1230
				1229	1230	1229	1229	1228	1229	1228	1229	1229	1228	1229	1229	1229	1228	1229	1229	1229	1229
				1229	1230	1229	1229	1229	1230	1229	1229	1229	1229	1229	1229	1230	1229	1229	1229	1230	1230
				1229	1229	1228	1228	1228	1229	1228	1229	1229	1228	1229	1228	1229	1228	1229	1228	1229	1229
				1229	1230	1229	1229	1229	1230	1229	1229	1229	1229	1229	1229	1230	1229	1229	1229	1230	1230
				1229	1229	1228	1228	1228	1229	1229	1229	1229	1228	1229	1229	1229	1228	1229	1229	1229	1229
				1229	1230	1229	1229	1228	1230	1229	1229	1229	1229	1229	1229	1229	1228	1229	1229	1230	1229
				1229	1230	1229	1229	1229	1230	1229	1229	1229	1229	1229	1229	1230	1228	1229	1229	1230	1230
				1229	1230	1229	1229	1229	1230	1229	1229	1229	1229	1229	1229	1230	1228	1229	1229	1229	1229
				1229	1229	1229	1229	1228	1230	1228	1229	1229	1228	1229	1229	1229	1228	1229	1229	1229	1229
				1229	1231	1229	1229	1229	1231	1229	1230	1230	1229	1230	1229	1230	1229	1230	1229	1230	1230
				1229	1229	1229	1228	1228	1230	1228	1229	1229	1228	1229	1229	1229	1228	1229	1229	1229	1229
				1229	1230	1229	1229	1229	1230	1229	1229	1229	1229	1229	1229	1230	1229	1229	1229	1230	1230
				1229	1230	1229	1228	1228	1230	1228	1229	1229	1229	1229	1229	1229	1228	1229	1229	1229	1229
				1229	1231	1229	1229	1229	1231	1229	1230	1229	1229	1230	1229	1230	1229	1230	1229	1230	1230
				1229	1230	1229	1229	1229	1230	1229	1229	1229	1229	1229	1229	1229	1228	1229	1229	1229	1229
				1229	1230	1229	1229	1229	1230	1229	1229	1229	1229	1229	1229	1230	1228	1229	1229	1230	1229
				1229	1230	1229	1229	1229	1230	1228	1229	1229	1229	1229	1229	1229	1228	1229	1229	1230	1229
				1229	1230	1229	1228	1228	1229	1228	1229	1229	1228	1229	1228	1229	1228	1229	1229	1230	1229
				1229	1229	1228	1228	1228	1228	1227	1228	1228	1228	1228	1228	1228	1228	1229	1229	1229	1229
				1229	1229	1228	1228	1227	1228	1227	1228	1227	1227	1228	1227	1228	1227	1228	1228	1229	1229
				>;

			PS_Config_Lmt_FW_CC_P = <
				112 112 112 112 112 112 112 112 112 112 112 112 112 112 112 112 112 112
				112 112 112 112 112 112 112 112 112 112 112 112 112 112 112 112 112 112
				112 112 112 112 112 112 112 112 112 112 112 112 112 112 112 112 112 112
				112 112 112 112 112 112 112 112 112 112 112 112 112 112 112 112 112 112
				112 112 112 112 112 112 112 112 112 112 112 112 112 112 112 112 112 112
				112 112 112 112 112 112 112 112 112 112 112 112 112 112 112 112 112 112
				112 112 112 112 112 112 112 112 112 112 112 112 112 112 112 112 112 112
				112 112 112 112 112 112 112 112 112 112 112 112 112 112 112 112 112 112
				112 112 112 112 112 112 112 112 112 112 112 112 112 112 112 112 112 112
				112 112 112 112 112 112 112 112 112 112 112 112 112 112 112 112 112 112
				112 112 112 112 112 112 112 112 112 112 112 112 112 112 112 112 112 112
				112 112 112 112 112 112 112 112 112 112 112 112 112 112 112 112 112 112
				112 112 112 112 112 112 112 112 112 112 112 112 112 112 112 112 112 112
				112 112 112 112 112 112 112 112 112 112 112 112 112 112 112 112 112 112
				112 112 112 112 112 112 112 112 112 112 112 112 112 112 112 112 112 112
				112 112 112 112 112 112 112 112 112 112 112 112 112 112 112 112 112 112
				112 112 112 112 112 112 112 112 112 112 112 112 112 112 112 112 112 112
				112 112 112 112 112 112 112 112 112 112 112 112 112 112 112 112 112 112
				112 112 112 112 112 112 112 112 112 112 112 112 112 112 112 112 112 112
				112 112 112 112 112 112 112 112 112 112 112 112 112 112 112 112 112 112
				112 112 112 112 112 112 112 112 112 112 112 112 112 112 112 112 112 112
				112 112 112 112 112 112 112 112 112 112 112 112 112 112 112 112 112 112
				112 112 112 112 112 112 112 112 112 112 112 112 112 112 112 112 112 112
				112 112 112 112 112 112 112 112 112 112 112 112 112 112 112 112 112 112
				112 112 112 112 112 112 112 112 112 112 112 112 112 112 112 112 112 112
				112 112 112 112 112 112 112 112 112 112 112 112 112 112 112 112 112 112
				112 112 112 112 112 112 112 112 112 112 112 112 112 112 112 112 112 112
				112 112 112 112 112 112 112 112 112 112 112 112 112 112 112 112 112 112
				112 112 112 112 112 112 112 112 112 112 112 112 112 112 112 112 112 112
				112 112 112 112 112 112 112 112 112 112 112 112 112 112 112 112 112 112
				112 112 112 112 112 112 112 112 112 112 112 112 112 112 112 112 112 112
				112 112 112 112 112 112 112 112 112 112 112 112 112 112 112 112 112 112
				112 112 112 112 112 112 112 112 112 112 112 112 112 112 112 112 112 112
				112 112 112 112 112 112 112 112 112 112 112 112 112 112 112 112 112 112
				112 112 112 112 112 112 112 112 112 112 112 112 112 112 112 112 112 112
				112 112 112 112 112 112 112 112 112 112 112 112 112 112 112 112 112 112
				112 112 112 112 112 112 112 112 112 112 112 112 112 112 112 112 112 112
				112 112 112 112 112 112 112 112 112 112 112 112 112 112 112 112 112 112
				112 112 112 112 112 112 112 112 112 112 112 112 112 112 112 112 112 112
				>;

			PS_Config_Lmt_FW_CC_N = <
				(-112) (-112) (-112) (-112) (-112) (-112) (-112) (-112) (-112) (-112) (-112) (-112) (-112) (-112) (-112) (-112) (-112) (-112)
				(-112) (-112) (-112) (-112) (-112) (-112) (-112) (-112) (-112) (-112) (-112) (-112) (-112) (-112) (-112) (-112) (-112) (-112)
				(-112) (-112) (-112) (-112) (-112) (-112) (-112) (-112) (-112) (-112) (-112) (-112) (-112) (-112) (-112) (-112) (-112) (-112)
				(-112) (-112) (-112) (-112) (-112) (-112) (-112) (-112) (-112) (-112) (-112) (-112) (-112) (-112) (-112) (-112) (-112) (-112)
				(-112) (-112) (-112) (-112) (-112) (-112) (-112) (-112) (-112) (-112) (-112) (-112) (-112) (-112) (-112) (-112) (-112) (-112)
				(-112) (-112) (-112) (-112) (-112) (-112) (-112) (-112) (-112) (-112) (-112) (-112) (-112) (-112) (-112) (-112) (-112) (-112)
				(-112) (-112) (-112) (-112) (-112) (-112) (-112) (-112) (-112) (-112) (-112) (-112) (-112) (-112) (-112) (-112) (-112) (-112)
				(-112) (-112) (-112) (-112) (-112) (-112) (-112) (-112) (-112) (-112) (-112) (-112) (-112) (-112) (-112) (-112) (-112) (-112)
				(-112) (-112) (-112) (-112) (-112) (-112) (-112) (-112) (-112) (-112) (-112) (-112) (-112) (-112) (-112) (-112) (-112) (-112)
				(-112) (-112) (-112) (-112) (-112) (-112) (-112) (-112) (-112) (-112) (-112) (-112) (-112) (-112) (-112) (-112) (-112) (-112)
				(-112) (-112) (-112) (-112) (-112) (-112) (-112) (-112) (-112) (-112) (-112) (-112) (-112) (-112) (-112) (-112) (-112) (-112)
				(-112) (-112) (-112) (-112) (-112) (-112) (-112) (-112) (-112) (-112) (-112) (-112) (-112) (-112) (-112) (-112) (-112) (-112)
				(-112) (-112) (-112) (-112) (-112) (-112) (-112) (-112) (-112) (-112) (-112) (-112) (-112) (-112) (-112) (-112) (-112) (-112)
				(-112) (-112) (-112) (-112) (-112) (-112) (-112) (-112) (-112) (-112) (-112) (-112) (-112) (-112) (-112) (-112) (-112) (-112)
				(-112) (-112) (-112) (-112) (-112) (-112) (-112) (-112) (-112) (-112) (-112) (-112) (-112) (-112) (-112) (-112) (-112) (-112)
				(-112) (-112) (-112) (-112) (-112) (-112) (-112) (-112) (-112) (-112) (-112) (-112) (-112) (-112) (-112) (-112) (-112) (-112)
				(-112) (-112) (-112) (-112) (-112) (-112) (-112) (-112) (-112) (-112) (-112) (-112) (-112) (-112) (-112) (-112) (-112) (-112)
				(-112) (-112) (-112) (-112) (-112) (-112) (-112) (-112) (-112) (-112) (-112) (-112) (-112) (-112) (-112) (-112) (-112) (-112)
				(-112) (-112) (-112) (-112) (-112) (-112) (-112) (-112) (-112) (-112) (-112) (-112) (-112) (-112) (-112) (-112) (-112) (-112)
				(-112) (-112) (-112) (-112) (-112) (-112) (-112) (-112) (-112) (-112) (-112) (-112) (-112) (-112) (-112) (-112) (-112) (-112)
				(-112) (-112) (-112) (-112) (-112) (-112) (-112) (-112) (-112) (-112) (-112) (-112) (-112) (-112) (-112) (-112) (-112) (-112)
				(-112) (-112) (-112) (-112) (-112) (-112) (-112) (-112) (-112) (-112) (-112) (-112) (-112) (-112) (-112) (-112) (-112) (-112)
				(-112) (-112) (-112) (-112) (-112) (-112) (-112) (-112) (-112) (-112) (-112) (-112) (-112) (-112) (-112) (-112) (-112) (-112)
				(-112) (-112) (-112) (-112) (-112) (-112) (-112) (-112) (-112) (-112) (-112) (-112) (-112) (-112) (-112) (-112) (-112) (-112)
				(-112) (-112) (-112) (-112) (-112) (-112) (-112) (-112) (-112) (-112) (-112) (-112) (-112) (-112) (-112) (-112) (-112) (-112)
				(-112) (-112) (-112) (-112) (-112) (-112) (-112) (-112) (-112) (-112) (-112) (-112) (-112) (-112) (-112) (-112) (-112) (-112)
				(-112) (-112) (-112) (-112) (-112) (-112) (-112) (-112) (-112) (-112) (-112) (-112) (-112) (-112) (-112) (-112) (-112) (-112)
				(-112) (-112) (-112) (-112) (-112) (-112) (-112) (-112) (-112) (-112) (-112) (-112) (-112) (-112) (-112) (-112) (-112) (-112)
				(-112) (-112) (-112) (-112) (-112) (-112) (-112) (-112) (-112) (-112) (-112) (-112) (-112) (-112) (-112) (-112) (-112) (-112)
				(-112) (-112) (-112) (-112) (-112) (-112) (-112) (-112) (-112) (-112) (-112) (-112) (-112) (-112) (-112) (-112) (-112) (-112)
				(-112) (-112) (-112) (-112) (-112) (-112) (-112) (-112) (-112) (-112) (-112) (-112) (-112) (-112) (-112) (-112) (-112) (-112)
				(-112) (-112) (-112) (-112) (-112) (-112) (-112) (-112) (-112) (-112) (-112) (-112) (-112) (-112) (-112) (-112) (-112) (-112)
				(-112) (-112) (-112) (-112) (-112) (-112) (-112) (-112) (-112) (-112) (-112) (-112) (-112) (-112) (-112) (-112) (-112) (-112)
				(-112) (-112) (-112) (-112) (-112) (-112) (-112) (-112) (-112) (-112) (-112) (-112) (-112) (-112) (-112) (-112) (-112) (-112)
				(-112) (-112) (-112) (-112) (-112) (-112) (-112) (-112) (-112) (-112) (-112) (-112) (-112) (-112) (-112) (-112) (-112) (-112)
				(-112) (-112) (-112) (-112) (-112) (-112) (-112) (-112) (-112) (-112) (-112) (-112) (-112) (-112) (-112) (-112) (-112) (-112)
				(-112) (-112) (-112) (-112) (-112) (-112) (-112) (-112) (-112) (-112) (-112) (-112) (-112) (-112) (-112) (-112) (-112) (-112)
				(-112) (-112) (-112) (-112) (-112) (-112) (-112) (-112) (-112) (-112) (-112) (-112) (-112) (-112) (-112) (-112) (-112) (-112)
				(-112) (-112) (-112) (-112) (-112) (-112) (-112) (-112) (-112) (-112) (-112) (-112) (-112) (-112) (-112) (-112) (-112) (-112)
				>;

			PS_Config_Lmt_FW_Diff_P = <
				65535 75 75 75 75 75 75 75 75 75 75 75 75 75 75 75 75 65535
				75 75 75 75 75 75 75 75 75 75 75 75 75 75 75 75 75 75
				75 75 75 75 75 75 75 75 75 75 75 75 75 75 75 75 75 75
				75 75 75 75 75 75 75 75 75 75 75 75 75 75 75 75 75 75
				75 75 75 75 75 75 75 75 75 75 75 75 75 75 75 75 75 75
				75 75 75 75 75 75 75 75 75 75 75 75 75 75 75 75 75 75
				75 75 75 75 75 75 75 75 75 75 75 75 75 75 75 75 75 75
				75 75 75 75 75 75 75 75 75 75 75 75 75 75 75 75 75 75
				75 75 75 75 75 75 75 75 75 75 75 75 75 75 75 75 75 75
				75 75 75 75 75 75 75 75 75 75 75 75 75 75 75 75 75 75
				75 75 75 75 75 75 75 75 75 75 75 75 75 75 75 75 75 75
				75 75 75 75 75 75 75 75 75 75 75 75 75 75 75 75 75 75
				75 75 75 75 75 75 75 75 75 75 75 75 75 75 75 75 75 75
				75 75 75 75 75 75 75 75 75 75 75 75 75 75 75 75 75 75
				75 75 75 75 75 75 75 75 75 75 75 75 75 75 75 75 75 75
				75 75 75 75 75 75 75 75 75 75 75 75 75 75 75 75 75 75
				75 75 75 75 75 75 75 75 75 75 75 75 75 75 75 75 75 75
				75 75 75 75 75 75 75 75 75 75 75 75 75 75 75 75 75 75
				75 75 75 75 75 75 75 75 75 75 75 75 75 75 75 75 75 75
				75 75 75 75 75 75 75 75 75 75 75 75 75 75 75 75 75 75
				75 75 75 75 75 75 75 75 75 75 75 75 75 75 75 75 75 75
				75 75 75 75 75 75 75 75 75 75 75 75 75 75 75 75 75 75
				75 75 75 75 75 75 75 75 75 75 75 75 75 75 75 75 75 75
				75 75 75 75 75 75 75 75 75 75 75 75 75 75 75 75 75 75
				75 75 75 75 75 75 75 75 75 75 75 75 75 75 75 75 75 75
				75 75 75 75 75 75 75 75 75 75 75 75 75 75 75 75 75 75
				75 75 75 75 75 75 75 75 75 75 75 75 75 75 75 75 75 75
				75 75 75 75 75 75 75 75 75 75 75 75 75 75 75 75 75 75
				75 75 75 75 75 75 75 75 75 75 75 75 75 75 75 75 75 75
				75 75 75 75 75 75 75 75 75 75 75 75 75 75 75 75 75 75
				75 75 75 75 75 75 75 75 75 75 75 75 75 75 75 75 75 75
				75 75 75 75 75 75 75 75 75 75 75 75 75 75 75 75 75 75
				75 75 75 75 75 75 75 75 75 75 75 75 75 75 75 75 75 75
				75 75 75 75 75 75 75 75 75 75 75 75 75 75 75 75 75 75
				75 75 75 75 75 75 75 75 75 75 75 75 75 75 75 75 75 75
				75 75 75 75 75 75 75 75 75 75 75 75 75 75 75 75 75 75
				75 75 75 75 75 75 75 75 75 75 75 75 75 75 75 75 75 75
				75 75 75 75 75 75 75 75 75 75 75 75 75 75 75 75 75 75
				65535 75 75 75 75 75 75 75 75 75 75 75 75 75 75 75 75 65535
				>;

			PS_Config_Lmt_FW_Diff_N = <
				(-65535) (-75) (-75) (-75) (-75) (-75) (-75) (-75) (-75) (-75) (-75) (-75) (-75) (-75) (-75) (-75) (-75) (-65535)
				(-75) (-75) (-75) (-75) (-75) (-75) (-75) (-75) (-75) (-75) (-75) (-75) (-75) (-75) (-75) (-75) (-75) (-75)
				(-75) (-75) (-75) (-75) (-75) (-75) (-75) (-75) (-75) (-75) (-75) (-75) (-75) (-75) (-75) (-75) (-75) (-75)
				(-75) (-75) (-75) (-75) (-75) (-75) (-75) (-75) (-75) (-75) (-75) (-75) (-75) (-75) (-75) (-75) (-75) (-75)
				(-75) (-75) (-75) (-75) (-75) (-75) (-75) (-75) (-75) (-75) (-75) (-75) (-75) (-75) (-75) (-75) (-75) (-75)
				(-75) (-75) (-75) (-75) (-75) (-75) (-75) (-75) (-75) (-75) (-75) (-75) (-75) (-75) (-75) (-75) (-75) (-75)
				(-75) (-75) (-75) (-75) (-75) (-75) (-75) (-75) (-75) (-75) (-75) (-75) (-75) (-75) (-75) (-75) (-75) (-75)
				(-75) (-75) (-75) (-75) (-75) (-75) (-75) (-75) (-75) (-75) (-75) (-75) (-75) (-75) (-75) (-75) (-75) (-75)
				(-75) (-75) (-75) (-75) (-75) (-75) (-75) (-75) (-75) (-75) (-75) (-75) (-75) (-75) (-75) (-75) (-75) (-75)
				(-75) (-75) (-75) (-75) (-75) (-75) (-75) (-75) (-75) (-75) (-75) (-75) (-75) (-75) (-75) (-75) (-75) (-75)
				(-75) (-75) (-75) (-75) (-75) (-75) (-75) (-75) (-75) (-75) (-75) (-75) (-75) (-75) (-75) (-75) (-75) (-75)
				(-75) (-75) (-75) (-75) (-75) (-75) (-75) (-75) (-75) (-75) (-75) (-75) (-75) (-75) (-75) (-75) (-75) (-75)
				(-75) (-75) (-75) (-75) (-75) (-75) (-75) (-75) (-75) (-75) (-75) (-75) (-75) (-75) (-75) (-75) (-75) (-75)
				(-75) (-75) (-75) (-75) (-75) (-75) (-75) (-75) (-75) (-75) (-75) (-75) (-75) (-75) (-75) (-75) (-75) (-75)
				(-75) (-75) (-75) (-75) (-75) (-75) (-75) (-75) (-75) (-75) (-75) (-75) (-75) (-75) (-75) (-75) (-75) (-75)
				(-75) (-75) (-75) (-75) (-75) (-75) (-75) (-75) (-75) (-75) (-75) (-75) (-75) (-75) (-75) (-75) (-75) (-75)
				(-75) (-75) (-75) (-75) (-75) (-75) (-75) (-75) (-75) (-75) (-75) (-75) (-75) (-75) (-75) (-75) (-75) (-75)
				(-75) (-75) (-75) (-75) (-75) (-75) (-75) (-75) (-75) (-75) (-75) (-75) (-75) (-75) (-75) (-75) (-75) (-75)
				(-75) (-75) (-75) (-75) (-75) (-75) (-75) (-75) (-75) (-75) (-75) (-75) (-75) (-75) (-75) (-75) (-75) (-75)
				(-75) (-75) (-75) (-75) (-75) (-75) (-75) (-75) (-75) (-75) (-75) (-75) (-75) (-75) (-75) (-75) (-75) (-75)
				(-75) (-75) (-75) (-75) (-75) (-75) (-75) (-75) (-75) (-75) (-75) (-75) (-75) (-75) (-75) (-75) (-75) (-75)
				(-75) (-75) (-75) (-75) (-75) (-75) (-75) (-75) (-75) (-75) (-75) (-75) (-75) (-75) (-75) (-75) (-75) (-75)
				(-75) (-75) (-75) (-75) (-75) (-75) (-75) (-75) (-75) (-75) (-75) (-75) (-75) (-75) (-75) (-75) (-75) (-75)
				(-75) (-75) (-75) (-75) (-75) (-75) (-75) (-75) (-75) (-75) (-75) (-75) (-75) (-75) (-75) (-75) (-75) (-75)
				(-75) (-75) (-75) (-75) (-75) (-75) (-75) (-75) (-75) (-75) (-75) (-75) (-75) (-75) (-75) (-75) (-75) (-75)
				(-75) (-75) (-75) (-75) (-75) (-75) (-75) (-75) (-75) (-75) (-75) (-75) (-75) (-75) (-75) (-75) (-75) (-75)
				(-75) (-75) (-75) (-75) (-75) (-75) (-75) (-75) (-75) (-75) (-75) (-75) (-75) (-75) (-75) (-75) (-75) (-75)
				(-75) (-75) (-75) (-75) (-75) (-75) (-75) (-75) (-75) (-75) (-75) (-75) (-75) (-75) (-75) (-75) (-75) (-75)
				(-75) (-75) (-75) (-75) (-75) (-75) (-75) (-75) (-75) (-75) (-75) (-75) (-75) (-75) (-75) (-75) (-75) (-75)
				(-75) (-75) (-75) (-75) (-75) (-75) (-75) (-75) (-75) (-75) (-75) (-75) (-75) (-75) (-75) (-75) (-75) (-75)
				(-75) (-75) (-75) (-75) (-75) (-75) (-75) (-75) (-75) (-75) (-75) (-75) (-75) (-75) (-75) (-75) (-75) (-75)
				(-75) (-75) (-75) (-75) (-75) (-75) (-75) (-75) (-75) (-75) (-75) (-75) (-75) (-75) (-75) (-75) (-75) (-75)
				(-75) (-75) (-75) (-75) (-75) (-75) (-75) (-75) (-75) (-75) (-75) (-75) (-75) (-75) (-75) (-75) (-75) (-75)
				(-75) (-75) (-75) (-75) (-75) (-75) (-75) (-75) (-75) (-75) (-75) (-75) (-75) (-75) (-75) (-75) (-75) (-75)
				(-75) (-75) (-75) (-75) (-75) (-75) (-75) (-75) (-75) (-75) (-75) (-75) (-75) (-75) (-75) (-75) (-75) (-75)
				(-75) (-75) (-75) (-75) (-75) (-75) (-75) (-75) (-75) (-75) (-75) (-75) (-75) (-75) (-75) (-75) (-75) (-75)
				(-75) (-75) (-75) (-75) (-75) (-75) (-75) (-75) (-75) (-75) (-75) (-75) (-75) (-75) (-75) (-75) (-75) (-75)
				(-75) (-75) (-75) (-75) (-75) (-75) (-75) (-75) (-75) (-75) (-75) (-75) (-75) (-75) (-75) (-75) (-75) (-75)
				(-65535) (-75) (-75) (-75) (-75) (-75) (-75) (-75) (-75) (-75) (-75) (-75) (-75) (-75) (-75) (-75) (-75) (-65535)
				>;

			PS_Config_Lmt_FW_Digital_Diff_P = <
				65535 75 75 75 75 75 75 75 75 75 75 75 75 75 75 75 75 65535
				75 75 75 75 75 75 75 75 75 75 75 75 75 75 75 75 75 75
				75 75 75 75 75 75 75 75 75 75 75 75 75 75 75 75 75 75
				75 75 75 75 75 75 75 75 75 75 75 75 75 75 75 75 75 75
				75 75 75 75 75 75 75 75 75 75 75 75 75 75 75 75 75 75
				75 75 75 75 75 75 75 75 75 75 75 75 75 75 75 75 75 75
				75 75 75 75 75 75 75 75 75 75 75 75 75 75 75 75 75 75
				75 75 75 75 75 75 75 75 75 75 75 75 75 75 75 75 75 75
				75 75 75 75 75 75 75 75 75 75 75 75 75 75 75 75 75 75
				75 75 75 75 75 75 75 75 75 75 75 75 75 75 75 75 75 75
				75 75 75 75 75 75 75 75 75 75 75 75 75 75 75 75 75 75
				75 75 75 75 75 75 75 75 75 75 75 75 75 75 75 75 75 75
				75 75 75 75 75 75 75 75 75 75 75 75 75 75 75 75 75 75
				75 75 75 75 75 75 75 75 75 75 75 75 75 75 75 75 75 75
				75 75 75 75 75 75 75 75 75 75 75 75 75 75 75 75 75 75
				75 75 75 75 75 75 75 75 75 75 75 75 75 75 75 75 75 75
				75 75 75 75 75 75 75 75 75 75 75 75 75 75 75 75 75 75
				75 75 75 75 75 75 75 75 75 75 75 75 75 75 75 75 75 75
				75 75 75 75 75 75 75 75 75 75 75 75 75 75 75 75 75 75
				75 75 75 75 75 75 75 75 75 75 75 75 75 75 75 75 75 75
				75 75 75 75 75 75 75 75 75 75 75 75 75 75 75 75 75 75
				75 75 75 75 75 75 75 75 75 75 75 75 75 75 75 75 75 75
				75 75 75 75 75 75 75 75 75 75 75 75 75 75 75 75 75 75
				75 75 75 75 75 75 75 75 75 75 75 75 75 75 75 75 75 75
				75 75 75 75 75 75 75 75 75 75 75 75 75 75 75 75 75 75
				75 75 75 75 75 75 75 75 75 75 75 75 75 75 75 75 75 75
				75 75 75 75 75 75 75 75 75 75 75 75 75 75 75 75 75 75
				75 75 75 75 75 75 75 75 75 75 75 75 75 75 75 75 75 75
				75 75 75 75 75 75 75 75 75 75 75 75 75 75 75 75 75 75
				75 75 75 75 75 75 75 75 75 75 75 75 75 75 75 75 75 75
				75 75 75 75 75 75 75 75 75 75 75 75 75 75 75 75 75 75
				75 75 75 75 75 75 75 75 75 75 75 75 75 75 75 75 75 75
				75 75 75 75 75 75 75 75 75 75 75 75 75 75 75 75 75 75
				75 75 75 75 75 75 75 75 75 75 75 75 75 75 75 75 75 75
				75 75 75 75 75 75 75 75 75 75 75 75 75 75 75 75 75 75
				75 75 75 75 75 75 75 75 75 75 75 75 75 75 75 75 75 75
				75 75 75 75 75 75 75 75 75 75 75 75 75 75 75 75 75 75
				75 75 75 75 75 75 75 75 75 75 75 75 75 75 75 75 75 75
				65535 75 75 75 75 75 75 75 75 75 75 75 75 75 75 75 75 65535
				>;

			PS_Config_Lmt_FW_Digital_Diff_N = <
				(-65535) (-75) (-75) (-75) (-75) (-75) (-75) (-75) (-75) (-75) (-75) (-75) (-75) (-75) (-75) (-75) (-75) (-65535)
				(-75) (-75) (-75) (-75) (-75) (-75) (-75) (-75) (-75) (-75) (-75) (-75) (-75) (-75) (-75) (-75) (-75) (-75)
				(-75) (-75) (-75) (-75) (-75) (-75) (-75) (-75) (-75) (-75) (-75) (-75) (-75) (-75) (-75) (-75) (-75) (-75)
				(-75) (-75) (-75) (-75) (-75) (-75) (-75) (-75) (-75) (-75) (-75) (-75) (-75) (-75) (-75) (-75) (-75) (-75)
				(-75) (-75) (-75) (-75) (-75) (-75) (-75) (-75) (-75) (-75) (-75) (-75) (-75) (-75) (-75) (-75) (-75) (-75)
				(-75) (-75) (-75) (-75) (-75) (-75) (-75) (-75) (-75) (-75) (-75) (-75) (-75) (-75) (-75) (-75) (-75) (-75)
				(-75) (-75) (-75) (-75) (-75) (-75) (-75) (-75) (-75) (-75) (-75) (-75) (-75) (-75) (-75) (-75) (-75) (-75)
				(-75) (-75) (-75) (-75) (-75) (-75) (-75) (-75) (-75) (-75) (-75) (-75) (-75) (-75) (-75) (-75) (-75) (-75)
				(-75) (-75) (-75) (-75) (-75) (-75) (-75) (-75) (-75) (-75) (-75) (-75) (-75) (-75) (-75) (-75) (-75) (-75)
				(-75) (-75) (-75) (-75) (-75) (-75) (-75) (-75) (-75) (-75) (-75) (-75) (-75) (-75) (-75) (-75) (-75) (-75)
				(-75) (-75) (-75) (-75) (-75) (-75) (-75) (-75) (-75) (-75) (-75) (-75) (-75) (-75) (-75) (-75) (-75) (-75)
				(-75) (-75) (-75) (-75) (-75) (-75) (-75) (-75) (-75) (-75) (-75) (-75) (-75) (-75) (-75) (-75) (-75) (-75)
				(-75) (-75) (-75) (-75) (-75) (-75) (-75) (-75) (-75) (-75) (-75) (-75) (-75) (-75) (-75) (-75) (-75) (-75)
				(-75) (-75) (-75) (-75) (-75) (-75) (-75) (-75) (-75) (-75) (-75) (-75) (-75) (-75) (-75) (-75) (-75) (-75)
				(-75) (-75) (-75) (-75) (-75) (-75) (-75) (-75) (-75) (-75) (-75) (-75) (-75) (-75) (-75) (-75) (-75) (-75)
				(-75) (-75) (-75) (-75) (-75) (-75) (-75) (-75) (-75) (-75) (-75) (-75) (-75) (-75) (-75) (-75) (-75) (-75)
				(-75) (-75) (-75) (-75) (-75) (-75) (-75) (-75) (-75) (-75) (-75) (-75) (-75) (-75) (-75) (-75) (-75) (-75)
				(-75) (-75) (-75) (-75) (-75) (-75) (-75) (-75) (-75) (-75) (-75) (-75) (-75) (-75) (-75) (-75) (-75) (-75)
				(-75) (-75) (-75) (-75) (-75) (-75) (-75) (-75) (-75) (-75) (-75) (-75) (-75) (-75) (-75) (-75) (-75) (-75)
				(-75) (-75) (-75) (-75) (-75) (-75) (-75) (-75) (-75) (-75) (-75) (-75) (-75) (-75) (-75) (-75) (-75) (-75)
				(-75) (-75) (-75) (-75) (-75) (-75) (-75) (-75) (-75) (-75) (-75) (-75) (-75) (-75) (-75) (-75) (-75) (-75)
				(-75) (-75) (-75) (-75) (-75) (-75) (-75) (-75) (-75) (-75) (-75) (-75) (-75) (-75) (-75) (-75) (-75) (-75)
				(-75) (-75) (-75) (-75) (-75) (-75) (-75) (-75) (-75) (-75) (-75) (-75) (-75) (-75) (-75) (-75) (-75) (-75)
				(-75) (-75) (-75) (-75) (-75) (-75) (-75) (-75) (-75) (-75) (-75) (-75) (-75) (-75) (-75) (-75) (-75) (-75)
				(-75) (-75) (-75) (-75) (-75) (-75) (-75) (-75) (-75) (-75) (-75) (-75) (-75) (-75) (-75) (-75) (-75) (-75)
				(-75) (-75) (-75) (-75) (-75) (-75) (-75) (-75) (-75) (-75) (-75) (-75) (-75) (-75) (-75) (-75) (-75) (-75)
				(-75) (-75) (-75) (-75) (-75) (-75) (-75) (-75) (-75) (-75) (-75) (-75) (-75) (-75) (-75) (-75) (-75) (-75)
				(-75) (-75) (-75) (-75) (-75) (-75) (-75) (-75) (-75) (-75) (-75) (-75) (-75) (-75) (-75) (-75) (-75) (-75)
				(-75) (-75) (-75) (-75) (-75) (-75) (-75) (-75) (-75) (-75) (-75) (-75) (-75) (-75) (-75) (-75) (-75) (-75)
				(-75) (-75) (-75) (-75) (-75) (-75) (-75) (-75) (-75) (-75) (-75) (-75) (-75) (-75) (-75) (-75) (-75) (-75)
				(-75) (-75) (-75) (-75) (-75) (-75) (-75) (-75) (-75) (-75) (-75) (-75) (-75) (-75) (-75) (-75) (-75) (-75)
				(-75) (-75) (-75) (-75) (-75) (-75) (-75) (-75) (-75) (-75) (-75) (-75) (-75) (-75) (-75) (-75) (-75) (-75)
				(-75) (-75) (-75) (-75) (-75) (-75) (-75) (-75) (-75) (-75) (-75) (-75) (-75) (-75) (-75) (-75) (-75) (-75)
				(-75) (-75) (-75) (-75) (-75) (-75) (-75) (-75) (-75) (-75) (-75) (-75) (-75) (-75) (-75) (-75) (-75) (-75)
				(-75) (-75) (-75) (-75) (-75) (-75) (-75) (-75) (-75) (-75) (-75) (-75) (-75) (-75) (-75) (-75) (-75) (-75)
				(-75) (-75) (-75) (-75) (-75) (-75) (-75) (-75) (-75) (-75) (-75) (-75) (-75) (-75) (-75) (-75) (-75) (-75)
				(-75) (-75) (-75) (-75) (-75) (-75) (-75) (-75) (-75) (-75) (-75) (-75) (-75) (-75) (-75) (-75) (-75) (-75)
				(-75) (-75) (-75) (-75) (-75) (-75) (-75) (-75) (-75) (-75) (-75) (-75) (-75) (-75) (-75) (-75) (-75) (-75)
				(-65535) (-75) (-75) (-75) (-75) (-75) (-75) (-75) (-75) (-75) (-75) (-75) (-75) (-75) (-75) (-75) (-75) (-65535)
				>;

			PS_Config_Diff_Test_Frame = <50>;
			PS_Config_Digital_Diff_Test_Frame = <50>;
		};

		/* for Xiaomi O10U NT38771 TM6.83" panel module */
		novatek-mp-criteria-5999@0 {
			#address-cells = <1>;
			#size-cells = <0>;
			compatible = "novatek-mp-criteria-5999";

			/* MP Criteria */
			PS_Config_Lmt_Short_TXRX_P = <
				3500 3500 3500 3500 3500 3500 3500 3500 3500 3500 3500 3500 3500 3500 3500 3500 3500 3500
				3500 3500 3500 3500 3500 3500 3500 3500 3500 3500 3500 3500 3500 3500 3500 3500 3500 3500
				3500 3500 3500 3500 3500 3500 3500 3500 3500 3500 3500 3500 3500 3500 3500 3500 3500 3500
				3500 3500 3500 3500 3500 3500 3500 3500 3500 3500 3500 3500 3500 3500 3500 3500 3500 3500
				3500 3500 3500 3500 3500 3500 3500 3500 3500 3500 3500 3500 3500 3500 3500 3500 3500 3500
				3500 3500 3500 3500 3500 3500 3500 3500 3500 3500 3500 3500 3500 3500 3500 3500 3500 3500
				3500 3500 3500 3500 3500 3500 3500 3500 3500 3500 3500 3500 3500 3500 3500 3500 3500 3500
				3500 3500 3500 3500 3500 3500 3500 3500 3500 3500 3500 3500 3500 3500 3500 3500 3500 3500
				3500 3500 3500 3500 3500 3500 3500 3500 3500 3500 3500 3500 3500 3500 3500 3500 3500 3500
				3500 3500 3500 3500 3500 3500 3500 3500 3500 3500 3500 3500 3500 3500 3500 3500 3500 3500
				3500 3500 3500 3500 3500 3500 3500 3500 3500 3500 3500 3500 3500 3500 3500 3500 3500 3500
				3500 3500 3500 3500 3500 3500 3500 3500 3500 3500 3500 3500 3500 3500 3500 3500 3500 3500
				3500 3500 3500 3500 3500 3500 3500 3500 3500 3500 3500 3500 3500 3500 3500 3500 3500 3500
				3500 3500 3500 3500 3500 3500 3500 3500 3500 3500 3500 3500 3500 3500 3500 3500 3500 3500
				3500 3500 3500 3500 3500 3500 3500 3500 3500 3500 3500 3500 3500 3500 3500 3500 3500 3500
				3500 3500 3500 3500 3500 3500 3500 3500 3500 3500 3500 3500 3500 3500 3500 3500 3500 3500
				3500 3500 3500 3500 3500 3500 3500 3500 3500 3500 3500 3500 3500 3500 3500 3500 3500 3500
				3500 3500 3500 3500 3500 3500 3500 3500 3500 3500 3500 3500 3500 3500 3500 3500 3500 3500
				3500 3500 3500 3500 3500 3500 3500 3500 3500 3500 3500 3500 3500 3500 3500 3500 3500 3500
				3500 3500 3500 3500 3500 3500 3500 3500 3500 3500 3500 3500 3500 3500 3500 3500 3500 3500
				3500 3500 3500 3500 3500 3500 3500 3500 3500 3500 3500 3500 3500 3500 3500 3500 3500 3500
				3500 3500 3500 3500 3500 3500 3500 3500 3500 3500 3500 3500 3500 3500 3500 3500 3500 3500
				3500 3500 3500 3500 3500 3500 3500 3500 3500 3500 3500 3500 3500 3500 3500 3500 3500 3500
				3500 3500 3500 3500 3500 3500 3500 3500 3500 3500 3500 3500 3500 3500 3500 3500 3500 3500
				3500 3500 3500 3500 3500 3500 3500 3500 3500 3500 3500 3500 3500 3500 3500 3500 3500 3500
				3500 3500 3500 3500 3500 3500 3500 3500 3500 3500 3500 3500 3500 3500 3500 3500 3500 3500
				3500 3500 3500 3500 3500 3500 3500 3500 3500 3500 3500 3500 3500 3500 3500 3500 3500 3500
				3500 3500 3500 3500 3500 3500 3500 3500 3500 3500 3500 3500 3500 3500 3500 3500 3500 3500
				3500 3500 3500 3500 3500 3500 3500 3500 3500 3500 3500 3500 3500 3500 3500 3500 3500 3500
				3500 3500 3500 3500 3500 3500 3500 3500 3500 3500 3500 3500 3500 3500 3500 3500 3500 3500
				3500 3500 3500 3500 3500 3500 3500 3500 3500 3500 3500 3500 3500 3500 3500 3500 3500 3500
				3500 3500 3500 3500 3500 3500 3500 3500 3500 3500 3500 3500 3500 3500 3500 3500 3500 3500
				3500 3500 3500 3500 3500 3500 3500 3500 3500 3500 3500 3500 3500 3500 3500 3500 3500 3500
				3500 3500 3500 3500 3500 3500 3500 3500 3500 3500 3500 3500 3500 3500 3500 3500 3500 3500
				3500 3500 3500 3500 3500 3500 3500 3500 3500 3500 3500 3500 3500 3500 3500 3500 3500 3500
				3500 3500 3500 3500 3500 3500 3500 3500 3500 3500 3500 3500 3500 3500 3500 3500 3500 3500
				3500 3500 3500 3500 3500 3500 3500 3500 3500 3500 3500 3500 3500 3500 3500 3500 3500 3500
				3500 3500 3500 3500 3500 3500 3500 3500 3500 3500 3500 3500 3500 3500 3500 3500 3500 3500
				3500 3500 3500 3500 3500 3500 3500 3500 3500 3500 3500 3500 3500 3500 3500 3500 3500 3500
				>;

			PS_Config_Lmt_Short_TXRX_N = <
				1900 1900 1900 1900 1900 1900 1900 1900 1900 1900 1900 1900 1900 1900 1900 1900 1900 1900
				1900 1900 1900 1900 1900 1900 1900 1900 1900 1900 1900 1900 1900 1900 1900 1900 1900 1900
				1900 1900 1900 1900 1900 1900 1900 1900 1900 1900 1900 1900 1900 1900 1900 1900 1900 1900
				1900 1900 1900 1900 1900 1900 1900 1900 1900 1900 1900 1900 1900 1900 1900 1900 1900 1900
				1900 1900 1900 1900 1900 1900 1900 1900 1900 1900 1900 1900 1900 1900 1900 1900 1900 1900
				1900 1900 1900 1900 1900 1900 1900 1900 1900 1900 1900 1900 1900 1900 1900 1900 1900 1900
				1900 1900 1900 1900 1900 1900 1900 1900 1900 1900 1900 1900 1900 1900 1900 1900 1900 1900
				1900 1900 1900 1900 1900 1900 1900 1900 1900 1900 1900 1900 1900 1900 1900 1900 1900 1900
				1900 1900 1900 1900 1900 1900 1900 1900 1900 1900 1900 1900 1900 1900 1900 1900 1900 1900
				1900 1900 1900 1900 1900 1900 1900 1900 1900 1900 1900 1900 1900 1900 1900 1900 1900 1900
				1900 1900 1900 1900 1900 1900 1900 1900 1900 1900 1900 1900 1900 1900 1900 1900 1900 1900
				1900 1900 1900 1900 1900 1900 1900 1900 1900 1900 1900 1900 1900 1900 1900 1900 1900 1900
				1900 1900 1900 1900 1900 1900 1900 1900 1900 1900 1900 1900 1900 1900 1900 1900 1900 1900
				1900 1900 1900 1900 1900 1900 1900 1900 1900 1900 1900 1900 1900 1900 1900 1900 1900 1900
				1900 1900 1900 1900 1900 1900 1900 1900 1900 1900 1900 1900 1900 1900 1900 1900 1900 1900
				1900 1900 1900 1900 1900 1900 1900 1900 1900 1900 1900 1900 1900 1900 1900 1900 1900 1900
				1900 1900 1900 1900 1900 1900 1900 1900 1900 1900 1900 1900 1900 1900 1900 1900 1900 1900
				1900 1900 1900 1900 1900 1900 1900 1900 1900 1900 1900 1900 1900 1900 1900 1900 1900 1900
				1900 1900 1900 1900 1900 1900 1900 1900 1900 1900 1900 1900 1900 1900 1900 1900 1900 1900
				1900 1900 1900 1900 1900 1900 1900 1900 1900 1900 1900 1900 1900 1900 1900 1900 1900 1900
				1900 1900 1900 1900 1900 1900 1900 1900 1900 1900 1900 1900 1900 1900 1900 1900 1900 1900
				1900 1900 1900 1900 1900 1900 1900 1900 1900 1900 1900 1900 1900 1900 1900 1900 1900 1900
				1900 1900 1900 1900 1900 1900 1900 1900 1900 1900 1900 1900 1900 1900 1900 1900 1900 1900
				1900 1900 1900 1900 1900 1900 1900 1900 1900 1900 1900 1900 1900 1900 1900 1900 1900 1900
				1900 1900 1900 1900 1900 1900 1900 1900 1900 1900 1900 1900 1900 1900 1900 1900 1900 1900
				1900 1900 1900 1900 1900 1900 1900 1900 1900 1900 1900 1900 1900 1900 1900 1900 1900 1900
				1900 1900 1900 1900 1900 1900 1900 1900 1900 1900 1900 1900 1900 1900 1900 1900 1900 1900
				1900 1900 1900 1900 1900 1900 1900 1900 1900 1900 1900 1900 1900 1900 1900 1900 1900 1900
				1900 1900 1900 1900 1900 1900 1900 1900 1900 1900 1900 1900 1900 1900 1900 1900 1900 1900
				1900 1900 1900 1900 1900 1900 1900 1900 1900 1900 1900 1900 1900 1900 1900 1900 1900 1900
				1900 1900 1900 1900 1900 1900 1900 1900 1900 1900 1900 1900 1900 1900 1900 1900 1900 1900
				1900 1900 1900 1900 1900 1900 1900 1900 1900 1900 1900 1900 1900 1900 1900 1900 1900 1900
				1900 1900 1900 1900 1900 1900 1900 1900 1900 1900 1900 1900 1900 1900 1900 1900 1900 1900
				1900 1900 1900 1900 1900 1900 1900 1900 1900 1900 1900 1900 1900 1900 1900 1900 1900 1900
				1900 1900 1900 1900 1900 1900 1900 1900 1900 1900 1900 1900 1900 1900 1900 1900 1900 1900
				1900 1900 1900 1900 1900 1900 1900 1900 1900 1900 1900 1900 1900 1900 1900 1900 1900 1900
				1900 1900 1900 1900 1900 1900 1900 1900 1900 1900 1900 1900 1900 1900 1900 1900 1900 1900
				1900 1900 1900 1900 1900 1900 1900 1900 1900 1900 1900 1900 1900 1900 1900 1900 1900 1900
				1900 1900 1900 1900 1900 1900 1900 1900 1900 1900 1900 1900 1900 1900 1900 1900 1900 1900
				>;

			PS_Config_Lmt_Short_TXTX_P = <
				3500 3500 3500 3500 3500 3500 3500 3500 3500 3500 3500 3500 3500 3500 3500 3500 3500 3500
				>;

			PS_Config_Lmt_Short_TXTX_N = <
				1900 1900 1900 1900 1900 1900 1900 1900 1900 1900 1900 1900 1900 1900 1900 1900 1900 1900
				>;

			PS_Config_Lmt_Short_RXRX_P = <
				3500
				3500
				3500
				3500
				3500
				3500
				3500
				3500
				3500
				3500
				3500
				3500
				3500
				3500
				3500
				3500
				3500
				3500
				3500
				3500
				3500
				3500
				3500
				3500
				3500
				3500
				3500
				3500
				3500
				3500
				3500
				3500
				3500
				3500
				3500
				3500
				3500
				3500
				3500
				>;

			PS_Config_Lmt_Short_RXRX_N = <
				1900
				1900
				1900
				1900
				1900
				1900
				1900
				1900
				1900
				1900
				1900
				1900
				1900
				1900
				1900
				1900
				1900
				1900
				1900
				1900
				1900
				1900
				1900
				1900
				1900
				1900
				1900
				1900
				1900
				1900
				1900
				1900
				1900
				1900
				1900
				1900
				1900
				1900
				1900
				>;

			PS_Config_Lmt_Open_Mutual_P = <
				65535 2765 2998 2929 2995 2851 2972 2880 2840 2705 2860 2793 2853 2816 2834 2769 2576 65535
				2951 2918 2954 2941 2946 2856 2921 2888 2489 2315 2810 2802 2804 2829 2790 2786 2769 2620
				3023 2931 2907 2928 2901 2843 2874 2860 2927 2797 2751 2790 2759 2820 2749 2779 2753 2741
				3066 2924 2934 2920 2925 2833 2900 2851 2932 2768 2775 2780 2786 2813 2776 2769 2778 2738
				2978 2995 2981 2934 2901 2846 2878 2866 2910 2780 2752 2792 2763 2824 2753 2782 2756 2749
				2991 2993 2995 2920 2921 2831 2898 2850 2931 2765 2770 2779 2785 2812 2776 2769 2778 2739
				2991 3036 2996 2958 2925 2870 2902 2890 2934 2803 2772 2814 2786 2849 2779 2806 2779 2772
				2989 2995 3006 2927 2927 2837 2905 2857 2938 2772 2776 2783 2790 2819 2782 2778 2785 2745
				2966 2945 2920 2999 2976 2854 2887 2874 2920 2787 2756 2799 2772 2833 2765 2790 2763 2756
				3000 2945 2955 3008 3002 2854 2922 2876 2954 2785 2790 2799 2806 2834 2800 2790 2797 2753
				2956 2939 2912 3005 2958 2847 2881 2868 2914 2779 2751 2790 2765 2826 2758 2785 2756 2749
				2992 2942 2952 3000 3002 2851 2917 2873 2951 2782 2787 2795 2802 2829 2797 2787 2793 2752
				2973 2961 2932 2951 2918 2927 2971 2891 2935 2799 2770 2810 2783 2844 2778 2803 2775 2768
				3008 2958 2965 2945 2946 2932 2991 2887 2964 2793 2797 2804 2813 2839 2806 2797 2803 2760
				2985 2966 2935 2948 2915 2941 2956 2890 2932 2795 2766 2806 2780 2839 2775 2797 2770 2760
				3019 2958 2955 2931 2931 2914 2981 2871 2948 2776 2783 2789 2796 2822 2789 2779 2786 2745
				3030 2985 2944 2951 2914 2867 2900 2946 3000 2793 2766 2804 2779 2837 2772 2796 2768 2760
				3131 3000 2982 2946 2945 2861 2927 2952 3020 2789 2797 2802 2810 2834 2803 2795 2799 2755
				3363 3084 2998 2982 2938 2891 2920 2985 3015 2813 2787 2826 2800 2858 2793 2817 2790 2779
				2819 2854 2867 2856 2860 2778 2846 2802 2876 2983 2991 2999 3012 3036 3005 3002 3009 3080
				2799 2868 2847 2870 2841 2795 2826 2816 2857 2998 2972 3013 2992 3052 2989 3016 2991 3080
				2799 2833 2844 2831 2836 2756 2822 2780 2854 2964 2969 2978 2991 3015 2986 2981 2991 3040
				2789 2857 2834 2857 2826 2779 2810 2803 2844 2985 2956 2996 2978 3037 2978 3003 2978 3066
				2831 2866 2878 2864 2870 2792 2854 2813 2887 2998 3003 3012 3023 3046 3022 3084 3084 3009
				2804 2873 2851 2874 2846 2800 2830 2823 2861 3003 2976 3016 2993 3052 2995 3081 3067 3018
				2847 2880 2894 2880 2885 2809 2871 2831 2901 3010 3020 3025 3036 3057 3037 3091 3117 3022
				2800 2870 2850 2870 2840 2797 2827 2822 2857 2999 2973 3013 2989 3044 2992 3086 3062 3010
				2829 2863 2877 2863 2867 2793 2853 2812 2884 2992 2999 3003 3015 3106 3077 3013 3025 2999
				2823 2891 2873 2893 2864 2824 2851 2846 2881 3025 2999 3037 3018 3133 3086 3047 3025 3029
				2833 2864 2878 2864 2870 2799 2857 2822 2885 2996 3003 3008 3020 3097 3096 3018 3029 2998
				2837 2904 2885 2907 2877 2840 2866 2861 2893 3039 3013 3049 3027 3148 3094 3060 3037 3039
				2853 2883 2900 2885 2891 2823 2880 2843 2907 3018 3027 3096 3100 3059 3043 3040 3052 3016
				2856 2922 2904 2925 2897 2861 2885 2883 2911 3057 3032 3125 3113 3097 3047 3077 3054 3054
				2861 2894 2910 2895 2904 2833 2891 2856 2917 3032 3040 3097 3125 3069 3056 3054 3066 3033
				2836 2902 2885 2907 2880 2846 2868 2867 2894 3037 3013 3113 3091 3076 3032 3066 3044 3046
				2891 2928 2945 2932 2941 2874 2928 2891 2951 3133 3134 3073 3086 3101 3091 3094 3110 3080
				2856 2929 2915 2938 2911 2881 2900 2901 2928 3135 3118 3081 3057 3106 3064 3101 3086 3131
				2790 2905 2948 2937 2946 2884 2937 2905 2966 3144 3161 3081 3093 3106 3098 3107 3107 3137
				65535 2829 2944 2971 2938 2918 2935 2962 3005 3222 3175 3114 3091 3130 3103 3155 3093 65535
				>;

			PS_Config_Lmt_Open_Mutual_N = <
				(-65535) 1129 1224 1197 1223 1165 1214 1176 1160 1105 1168 1141 1165 1150 1158 1131 1052 (-65535)
				1205 1192 1206 1201 1204 1166 1193 1180 1017 945 1148 1144 1146 1155 1140 1138 1131 1070
				1235 1197 1187 1196 1185 1161 1174 1168 1195 1143 1123 1140 1127 1152 1123 1135 1125 1119
				1252 1194 1198 1192 1195 1157 1184 1165 1198 1130 1133 1136 1138 1149 1134 1131 1134 1118
				1216 1223 1217 1198 1185 1162 1176 1170 1188 1136 1124 1140 1129 1154 1125 1136 1126 1123
				1221 1223 1223 1192 1193 1157 1184 1164 1197 1129 1132 1135 1137 1148 1134 1131 1134 1119
				1221 1240 1224 1208 1195 1172 1186 1180 1198 1145 1132 1150 1138 1163 1135 1146 1135 1132
				1221 1223 1228 1195 1195 1159 1187 1167 1200 1132 1134 1137 1140 1151 1136 1134 1137 1121
				1212 1203 1192 1225 1216 1166 1179 1174 1192 1139 1126 1143 1132 1157 1129 1140 1129 1126
				1226 1203 1207 1228 1226 1166 1194 1175 1206 1137 1140 1143 1146 1158 1144 1140 1143 1125
				1208 1201 1190 1227 1208 1163 1177 1172 1190 1135 1123 1140 1129 1154 1126 1137 1126 1123
				1222 1202 1206 1226 1226 1165 1191 1173 1205 1136 1139 1141 1144 1155 1143 1139 1141 1124
				1215 1209 1198 1205 1192 1195 1213 1181 1199 1143 1132 1148 1137 1162 1134 1145 1133 1130
				1228 1208 1211 1203 1204 1198 1221 1179 1210 1141 1143 1146 1149 1159 1146 1143 1145 1128
				1219 1212 1199 1204 1191 1201 1208 1180 1198 1141 1130 1146 1136 1159 1133 1143 1132 1128
				1233 1208 1207 1197 1197 1190 1217 1173 1204 1134 1137 1139 1142 1152 1139 1135 1138 1121
				1238 1219 1202 1205 1190 1171 1184 1204 1226 1141 1130 1146 1135 1159 1132 1142 1130 1128
				1279 1226 1218 1204 1203 1169 1195 1206 1234 1139 1143 1144 1148 1158 1145 1141 1143 1125
				1373 1260 1224 1218 1200 1181 1192 1219 1231 1149 1139 1154 1144 1168 1141 1151 1140 1135
				1151 1166 1171 1166 1168 1134 1162 1144 1175 1219 1221 1225 1230 1240 1227 1226 1229 1258
				1143 1172 1163 1172 1161 1141 1154 1150 1167 1224 1214 1231 1222 1246 1221 1232 1221 1258
				1143 1157 1162 1157 1158 1126 1152 1136 1166 1210 1213 1216 1221 1231 1220 1217 1221 1242
				1139 1167 1158 1167 1154 1135 1148 1145 1162 1219 1208 1224 1216 1241 1216 1227 1216 1252
				1157 1170 1176 1170 1172 1140 1166 1149 1179 1224 1227 1230 1235 1244 1234 1260 1260 1229
				1146 1173 1165 1174 1162 1144 1156 1153 1169 1227 1216 1232 1223 1246 1223 1259 1253 1233
				1163 1176 1182 1176 1179 1147 1173 1157 1185 1230 1234 1235 1240 1249 1241 1263 1273 1234
				1144 1172 1164 1172 1160 1143 1155 1152 1167 1225 1215 1231 1221 1244 1222 1260 1250 1230
				1155 1169 1175 1169 1171 1141 1165 1148 1178 1222 1225 1227 1231 1268 1257 1231 1235 1225
				1153 1181 1173 1181 1170 1154 1165 1162 1177 1235 1225 1241 1233 1279 1260 1245 1235 1237
				1157 1170 1176 1170 1172 1143 1167 1152 1179 1224 1227 1228 1234 1265 1264 1233 1237 1224
				1159 1186 1179 1187 1175 1160 1170 1169 1181 1241 1231 1245 1237 1286 1264 1250 1241 1241
				1165 1177 1184 1179 1181 1153 1176 1161 1187 1233 1237 1264 1266 1249 1243 1242 1246 1232
				1166 1194 1186 1195 1183 1169 1179 1177 1189 1249 1238 1277 1271 1265 1245 1257 1248 1248
				1169 1182 1188 1183 1186 1157 1181 1166 1191 1238 1242 1265 1277 1253 1248 1248 1252 1239
				1158 1186 1179 1187 1176 1162 1172 1171 1182 1241 1231 1271 1263 1256 1238 1252 1244 1244
				1181 1196 1203 1198 1201 1174 1196 1181 1205 1279 1280 1255 1260 1267 1263 1264 1270 1258
				1166 1197 1191 1200 1189 1177 1184 1185 1196 1281 1274 1259 1249 1268 1252 1267 1260 1279
				1140 1187 1204 1199 1204 1178 1199 1187 1212 1284 1291 1259 1263 1268 1266 1269 1269 1281
				(-65535) 1155 1202 1213 1200 1192 1199 1210 1227 1316 1297 1272 1263 1278 1267 1289 1263 (-65535)
				>;

			PS_Config_Lmt_Open_SelfTX_P = <
				2451 2529 2543 2543 2555 2545 2538 2553 2528 2516 2539 2525 2525 2543 2530 2528 2513 2447
				>;

			PS_Config_Lmt_Open_SelfTX_N = <
				1001 1033 1039 1039 1043 1039 1036 1043 1032 1028 1037 1031 1031 1039 1034 1032 1027 999
				>;

			PS_Config_Lmt_Open_SelfRX_P = <
				2572
				2651
				2661
				2640
				2634
				2604
				2606
				2594
				2582
				2592
				2582
				2557
				2567
				2546
				2577
				2559
				2577
				2545
				2555
				2528
				2532
				2520
				2526
				2515
				2499
				2512
				2519
				2512
				2523
				2505
				2494
				2499
				2496
				2511
				2513
				2519
				2492
				2457
				2332
				>;

			PS_Config_Lmt_Open_SelfRX_N = <
				1050
				1083
				1087
				1078
				1076
				1064
				1064
				1060
				1054
				1059
				1054
				1045
				1049
				1040
				1053
				1045
				1053
				1039
				1043
				1032
				1034
				1030
				1032
				1027
				1021
				1026
				1029
				1026
				1031
				1023
				1018
				1021
				1020
				1025
				1027
				1029
				1018
				1003
				952
				>;

			PS_Config_Lmt_FW_Rawdata_P = <
				2866 2869 2869 2866 2866 2869 2867 2866 2866 2866 2869 2867 2866 2867 2867 2864 2867 2867
				2867 2869 2869 2866 2866 2870 2867 2866 2866 2866 2869 2867 2866 2867 2867 2864 2867 2867
				2867 2869 2869 2866 2866 2869 2867 2866 2866 2866 2869 2867 2866 2867 2867 2864 2867 2867
				2867 2869 2869 2867 2866 2869 2867 2866 2866 2866 2869 2867 2866 2867 2867 2864 2867 2867
				2866 2869 2869 2866 2867 2869 2867 2866 2866 2866 2869 2867 2866 2867 2867 2864 2867 2867
				2867 2869 2869 2866 2866 2869 2867 2866 2866 2866 2869 2867 2866 2867 2867 2864 2867 2867
				2867 2869 2869 2867 2866 2869 2867 2866 2867 2866 2869 2867 2866 2867 2867 2864 2867 2867
				2866 2869 2869 2866 2866 2870 2867 2866 2866 2866 2869 2867 2866 2867 2867 2864 2867 2867
				2866 2869 2869 2866 2866 2869 2867 2866 2866 2866 2869 2867 2866 2867 2867 2866 2867 2867
				2867 2869 2869 2866 2867 2869 2867 2866 2867 2866 2869 2867 2866 2867 2867 2864 2867 2867
				2867 2869 2869 2867 2866 2869 2867 2866 2866 2866 2869 2867 2866 2867 2866 2864 2867 2867
				2867 2869 2869 2867 2867 2869 2867 2866 2866 2866 2869 2867 2866 2867 2867 2864 2867 2867
				2866 2869 2869 2866 2866 2869 2867 2866 2866 2866 2869 2867 2866 2867 2867 2866 2867 2867
				2867 2869 2869 2867 2867 2869 2867 2866 2866 2866 2869 2867 2866 2869 2867 2866 2867 2867
				2866 2869 2869 2866 2866 2869 2867 2866 2866 2866 2869 2867 2866 2869 2867 2866 2867 2867
				2866 2869 2869 2866 2866 2869 2867 2866 2866 2866 2869 2867 2866 2867 2867 2864 2867 2867
				2866 2869 2869 2867 2866 2869 2867 2866 2866 2866 2869 2867 2866 2867 2867 2866 2867 2867
				2867 2869 2869 2866 2866 2869 2867 2866 2866 2866 2869 2867 2866 2867 2867 2866 2867 2867
				2866 2869 2869 2867 2866 2869 2867 2866 2866 2866 2869 2867 2866 2867 2867 2866 2867 2867
				2866 2869 2869 2866 2866 2869 2867 2864 2866 2866 2869 2867 2866 2867 2867 2866 2867 2867
				2866 2869 2869 2866 2866 2869 2867 2866 2866 2866 2869 2867 2866 2867 2867 2866 2867 2867
				2866 2869 2869 2866 2866 2869 2867 2864 2866 2866 2869 2867 2866 2867 2867 2866 2867 2867
				2866 2869 2869 2866 2867 2869 2867 2866 2866 2866 2869 2867 2866 2867 2867 2866 2867 2867
				2866 2869 2869 2866 2867 2869 2867 2866 2866 2866 2869 2867 2866 2867 2867 2866 2867 2867
				2866 2869 2869 2866 2867 2869 2867 2864 2866 2866 2869 2867 2866 2867 2867 2866 2867 2867
				2866 2869 2869 2866 2867 2869 2867 2866 2866 2866 2869 2867 2866 2867 2867 2866 2867 2867
				2866 2869 2869 2866 2867 2869 2867 2866 2866 2866 2869 2867 2866 2867 2867 2866 2867 2867
				2866 2869 2869 2866 2866 2869 2867 2866 2866 2866 2869 2867 2866 2867 2867 2866 2867 2867
				2866 2869 2869 2866 2867 2869 2867 2866 2866 2866 2869 2867 2866 2867 2867 2866 2867 2867
				2866 2869 2869 2866 2867 2869 2867 2866 2866 2866 2869 2867 2866 2867 2867 2866 2867 2867
				2866 2869 2869 2866 2866 2869 2867 2866 2866 2866 2869 2867 2866 2867 2867 2866 2867 2867
				2866 2869 2869 2866 2867 2869 2867 2866 2866 2866 2869 2867 2866 2867 2867 2866 2867 2867
				2866 2869 2869 2866 2867 2869 2867 2866 2866 2866 2869 2867 2866 2867 2867 2866 2867 2867
				2866 2869 2869 2866 2867 2869 2867 2866 2867 2866 2869 2867 2866 2867 2867 2866 2867 2867
				2866 2869 2869 2866 2867 2869 2867 2866 2866 2866 2869 2867 2866 2867 2867 2866 2867 2867
				2866 2869 2869 2866 2867 2869 2867 2866 2866 2866 2869 2867 2866 2867 2867 2866 2867 2867
				2866 2869 2869 2866 2867 2869 2867 2866 2866 2866 2869 2867 2866 2867 2867 2866 2867 2867
				2866 2869 2869 2866 2867 2869 2867 2866 2866 2866 2869 2867 2866 2867 2867 2866 2867 2867
				2866 2869 2869 2866 2867 2869 2867 2866 2866 2866 2869 2867 2866 2867 2867 2866 2867 2867
				>;

			PS_Config_Lmt_FW_Rawdata_N = <
				1228 1229 1229 1228 1228 1229 1229 1228 1228 1228 1229 1229 1228 1229 1229 1228 1229 1229
				1229 1229 1229 1228 1228 1230 1229 1228 1228 1228 1229 1229 1228 1229 1229 1228 1229 1229
				1229 1229 1229 1228 1228 1229 1229 1228 1228 1228 1229 1229 1228 1229 1229 1228 1229 1229
				1229 1229 1229 1229 1228 1229 1229 1228 1228 1228 1229 1229 1228 1229 1229 1228 1229 1229
				1228 1229 1229 1228 1229 1229 1229 1228 1228 1228 1229 1229 1228 1229 1229 1228 1229 1229
				1229 1229 1229 1228 1228 1229 1229 1228 1228 1228 1229 1229 1228 1229 1229 1228 1229 1229
				1229 1229 1229 1229 1228 1229 1229 1228 1229 1228 1229 1229 1228 1229 1229 1228 1229 1229
				1228 1229 1229 1228 1228 1230 1229 1228 1228 1228 1229 1229 1228 1229 1229 1228 1229 1229
				1228 1229 1229 1228 1228 1229 1229 1228 1228 1228 1229 1229 1228 1229 1229 1228 1229 1229
				1229 1229 1229 1228 1229 1229 1229 1228 1229 1228 1229 1229 1228 1229 1229 1228 1229 1229
				1229 1229 1229 1229 1228 1229 1229 1228 1228 1228 1229 1229 1228 1229 1228 1228 1229 1229
				1229 1229 1229 1229 1229 1229 1229 1228 1228 1228 1229 1229 1228 1229 1229 1228 1229 1229
				1228 1229 1229 1228 1228 1229 1229 1228 1228 1228 1229 1229 1228 1229 1229 1228 1229 1229
				1229 1229 1229 1229 1229 1229 1229 1228 1228 1228 1229 1229 1228 1229 1229 1228 1229 1229
				1228 1229 1229 1228 1228 1229 1229 1228 1228 1228 1229 1229 1228 1229 1229 1228 1229 1229
				1228 1229 1229 1228 1228 1229 1229 1228 1228 1228 1229 1229 1228 1229 1229 1228 1229 1229
				1228 1229 1229 1229 1228 1229 1229 1228 1228 1228 1229 1229 1228 1229 1229 1228 1229 1229
				1229 1229 1229 1228 1228 1229 1229 1228 1228 1228 1229 1229 1228 1229 1229 1228 1229 1229
				1228 1229 1229 1229 1228 1229 1229 1228 1228 1228 1229 1229 1228 1229 1229 1228 1229 1229
				1228 1229 1229 1228 1228 1229 1229 1228 1228 1228 1229 1229 1228 1229 1229 1228 1229 1229
				1228 1229 1229 1228 1228 1229 1229 1228 1228 1228 1229 1229 1228 1229 1229 1228 1229 1229
				1228 1229 1229 1228 1228 1229 1229 1228 1228 1228 1229 1229 1228 1229 1229 1228 1229 1229
				1228 1229 1229 1228 1229 1229 1229 1228 1228 1228 1229 1229 1228 1229 1229 1228 1229 1229
				1228 1229 1229 1228 1229 1229 1229 1228 1228 1228 1229 1229 1228 1229 1229 1228 1229 1229
				1228 1229 1229 1228 1229 1229 1229 1228 1228 1228 1229 1229 1228 1229 1229 1228 1229 1229
				1228 1229 1229 1228 1229 1229 1229 1228 1228 1228 1229 1229 1228 1229 1229 1228 1229 1229
				1228 1229 1229 1228 1229 1229 1229 1228 1228 1228 1229 1229 1228 1229 1229 1228 1229 1229
				1228 1229 1229 1228 1228 1229 1229 1228 1228 1228 1229 1229 1228 1229 1229 1228 1229 1229
				1228 1229 1229 1228 1229 1229 1229 1228 1228 1228 1229 1229 1228 1229 1229 1228 1229 1229
				1228 1229 1229 1228 1229 1229 1229 1228 1228 1228 1229 1229 1228 1229 1229 1228 1229 1229
				1228 1229 1229 1228 1228 1229 1229 1228 1228 1228 1229 1229 1228 1229 1229 1228 1229 1229
				1228 1229 1229 1228 1229 1229 1229 1228 1228 1228 1229 1229 1228 1229 1229 1228 1229 1229
				1228 1229 1229 1228 1229 1229 1229 1228 1228 1228 1229 1229 1228 1229 1229 1228 1229 1229
				1228 1229 1229 1228 1229 1229 1229 1228 1229 1228 1229 1229 1228 1229 1229 1228 1229 1229
				1228 1229 1229 1228 1229 1229 1229 1228 1228 1228 1229 1229 1228 1229 1229 1228 1229 1229
				1228 1229 1229 1228 1229 1229 1229 1228 1228 1228 1229 1229 1228 1229 1229 1228 1229 1229
				1228 1229 1229 1228 1229 1229 1229 1228 1228 1228 1229 1229 1228 1229 1229 1228 1229 1229
				1228 1229 1229 1228 1229 1229 1229 1228 1228 1228 1229 1229 1228 1229 1229 1228 1229 1229
				1228 1229 1229 1228 1229 1229 1229 1228 1228 1228 1229 1229 1228 1229 1229 1228 1229 1229
				>;

			PS_Config_Lmt_FW_CC_P = <
				80 80 80 80 80 80 80 80 80 80 80 80 80 80 80 80 80 80
				80 80 80 80 80 80 80 80 80 80 80 80 80 80 80 80 80 80
				80 80 80 80 80 80 80 80 80 80 80 80 80 80 80 80 80 80
				80 80 80 80 80 80 80 80 80 80 80 80 80 80 80 80 80 80
				80 80 80 80 80 80 80 80 80 80 80 80 80 80 80 80 80 80
				80 80 80 80 80 80 80 80 80 80 80 80 80 80 80 80 80 80
				80 80 80 80 80 80 80 80 80 80 80 80 80 80 80 80 80 80
				80 80 80 80 80 80 80 80 80 80 80 80 80 80 80 80 80 80
				80 80 80 80 80 80 80 80 80 80 80 80 80 80 80 80 80 80
				80 80 80 80 80 80 80 80 80 80 80 80 80 80 80 80 80 80
				80 80 80 80 80 80 80 80 80 80 80 80 80 80 80 80 80 80
				80 80 80 80 80 80 80 80 80 80 80 80 80 80 80 80 80 80
				80 80 80 80 80 80 80 80 80 80 80 80 80 80 80 80 80 80
				80 80 80 80 80 80 80 80 80 80 80 80 80 80 80 80 80 80
				80 80 80 80 80 80 80 80 80 80 80 80 80 80 80 80 80 80
				80 80 80 80 80 80 80 80 80 80 80 80 80 80 80 80 80 80
				80 80 80 80 80 80 80 80 80 80 80 80 80 80 80 80 80 80
				80 80 80 80 80 80 80 80 80 80 80 80 80 80 80 80 80 80
				80 80 80 80 80 80 80 80 80 80 80 80 80 80 80 80 80 80
				80 80 80 80 80 80 80 80 80 80 80 80 80 80 80 80 80 80
				80 80 80 80 80 80 80 80 80 80 80 80 80 80 80 80 80 80
				80 80 80 80 80 80 80 80 80 80 80 80 80 80 80 80 80 80
				80 80 80 80 80 80 80 80 80 80 80 80 80 80 80 80 80 80
				80 80 80 80 80 80 80 80 80 80 80 80 80 80 80 80 80 80
				80 80 80 80 80 80 80 80 80 80 80 80 80 80 80 80 80 80
				80 80 80 80 80 80 80 80 80 80 80 80 80 80 80 80 80 80
				80 80 80 80 80 80 80 80 80 80 80 80 80 80 80 80 80 80
				80 80 80 80 80 80 80 80 80 80 80 80 80 80 80 80 80 80
				80 80 80 80 80 80 80 80 80 80 80 80 80 80 80 80 80 80
				80 80 80 80 80 80 80 80 80 80 80 80 80 80 80 80 80 80
				80 80 80 80 80 80 80 80 80 80 80 80 80 80 80 80 80 80
				80 80 80 80 80 80 80 80 80 80 80 80 80 80 80 80 80 80
				80 80 80 80 80 80 80 80 80 80 80 80 80 80 80 80 80 80
				80 80 80 80 80 80 80 80 80 80 80 80 80 80 80 80 80 80
				80 80 80 80 80 80 80 80 80 80 80 80 80 80 80 80 80 80
				80 80 80 80 80 80 80 80 80 80 80 80 80 80 80 80 80 80
				80 80 80 80 80 80 80 80 80 80 80 80 80 80 80 80 80 80
				80 80 80 80 80 80 80 80 80 80 80 80 80 80 80 80 80 80
				80 80 80 80 80 80 80 80 80 80 80 80 80 80 80 80 80 80
				>;

			PS_Config_Lmt_FW_CC_N = <
				(-80) (-80) (-80) (-80) (-80) (-80) (-80) (-80) (-80) (-80) (-80) (-80) (-80) (-80) (-80) (-80) (-80) (-80)
				(-80) (-80) (-80) (-80) (-80) (-80) (-80) (-80) (-80) (-80) (-80) (-80) (-80) (-80) (-80) (-80) (-80) (-80)
				(-80) (-80) (-80) (-80) (-80) (-80) (-80) (-80) (-80) (-80) (-80) (-80) (-80) (-80) (-80) (-80) (-80) (-80)
				(-80) (-80) (-80) (-80) (-80) (-80) (-80) (-80) (-80) (-80) (-80) (-80) (-80) (-80) (-80) (-80) (-80) (-80)
				(-80) (-80) (-80) (-80) (-80) (-80) (-80) (-80) (-80) (-80) (-80) (-80) (-80) (-80) (-80) (-80) (-80) (-80)
				(-80) (-80) (-80) (-80) (-80) (-80) (-80) (-80) (-80) (-80) (-80) (-80) (-80) (-80) (-80) (-80) (-80) (-80)
				(-80) (-80) (-80) (-80) (-80) (-80) (-80) (-80) (-80) (-80) (-80) (-80) (-80) (-80) (-80) (-80) (-80) (-80)
				(-80) (-80) (-80) (-80) (-80) (-80) (-80) (-80) (-80) (-80) (-80) (-80) (-80) (-80) (-80) (-80) (-80) (-80)
				(-80) (-80) (-80) (-80) (-80) (-80) (-80) (-80) (-80) (-80) (-80) (-80) (-80) (-80) (-80) (-80) (-80) (-80)
				(-80) (-80) (-80) (-80) (-80) (-80) (-80) (-80) (-80) (-80) (-80) (-80) (-80) (-80) (-80) (-80) (-80) (-80)
				(-80) (-80) (-80) (-80) (-80) (-80) (-80) (-80) (-80) (-80) (-80) (-80) (-80) (-80) (-80) (-80) (-80) (-80)
				(-80) (-80) (-80) (-80) (-80) (-80) (-80) (-80) (-80) (-80) (-80) (-80) (-80) (-80) (-80) (-80) (-80) (-80)
				(-80) (-80) (-80) (-80) (-80) (-80) (-80) (-80) (-80) (-80) (-80) (-80) (-80) (-80) (-80) (-80) (-80) (-80)
				(-80) (-80) (-80) (-80) (-80) (-80) (-80) (-80) (-80) (-80) (-80) (-80) (-80) (-80) (-80) (-80) (-80) (-80)
				(-80) (-80) (-80) (-80) (-80) (-80) (-80) (-80) (-80) (-80) (-80) (-80) (-80) (-80) (-80) (-80) (-80) (-80)
				(-80) (-80) (-80) (-80) (-80) (-80) (-80) (-80) (-80) (-80) (-80) (-80) (-80) (-80) (-80) (-80) (-80) (-80)
				(-80) (-80) (-80) (-80) (-80) (-80) (-80) (-80) (-80) (-80) (-80) (-80) (-80) (-80) (-80) (-80) (-80) (-80)
				(-80) (-80) (-80) (-80) (-80) (-80) (-80) (-80) (-80) (-80) (-80) (-80) (-80) (-80) (-80) (-80) (-80) (-80)
				(-80) (-80) (-80) (-80) (-80) (-80) (-80) (-80) (-80) (-80) (-80) (-80) (-80) (-80) (-80) (-80) (-80) (-80)
				(-80) (-80) (-80) (-80) (-80) (-80) (-80) (-80) (-80) (-80) (-80) (-80) (-80) (-80) (-80) (-80) (-80) (-80)
				(-80) (-80) (-80) (-80) (-80) (-80) (-80) (-80) (-80) (-80) (-80) (-80) (-80) (-80) (-80) (-80) (-80) (-80)
				(-80) (-80) (-80) (-80) (-80) (-80) (-80) (-80) (-80) (-80) (-80) (-80) (-80) (-80) (-80) (-80) (-80) (-80)
				(-80) (-80) (-80) (-80) (-80) (-80) (-80) (-80) (-80) (-80) (-80) (-80) (-80) (-80) (-80) (-80) (-80) (-80)
				(-80) (-80) (-80) (-80) (-80) (-80) (-80) (-80) (-80) (-80) (-80) (-80) (-80) (-80) (-80) (-80) (-80) (-80)
				(-80) (-80) (-80) (-80) (-80) (-80) (-80) (-80) (-80) (-80) (-80) (-80) (-80) (-80) (-80) (-80) (-80) (-80)
				(-80) (-80) (-80) (-80) (-80) (-80) (-80) (-80) (-80) (-80) (-80) (-80) (-80) (-80) (-80) (-80) (-80) (-80)
				(-80) (-80) (-80) (-80) (-80) (-80) (-80) (-80) (-80) (-80) (-80) (-80) (-80) (-80) (-80) (-80) (-80) (-80)
				(-80) (-80) (-80) (-80) (-80) (-80) (-80) (-80) (-80) (-80) (-80) (-80) (-80) (-80) (-80) (-80) (-80) (-80)
				(-80) (-80) (-80) (-80) (-80) (-80) (-80) (-80) (-80) (-80) (-80) (-80) (-80) (-80) (-80) (-80) (-80) (-80)
				(-80) (-80) (-80) (-80) (-80) (-80) (-80) (-80) (-80) (-80) (-80) (-80) (-80) (-80) (-80) (-80) (-80) (-80)
				(-80) (-80) (-80) (-80) (-80) (-80) (-80) (-80) (-80) (-80) (-80) (-80) (-80) (-80) (-80) (-80) (-80) (-80)
				(-80) (-80) (-80) (-80) (-80) (-80) (-80) (-80) (-80) (-80) (-80) (-80) (-80) (-80) (-80) (-80) (-80) (-80)
				(-80) (-80) (-80) (-80) (-80) (-80) (-80) (-80) (-80) (-80) (-80) (-80) (-80) (-80) (-80) (-80) (-80) (-80)
				(-80) (-80) (-80) (-80) (-80) (-80) (-80) (-80) (-80) (-80) (-80) (-80) (-80) (-80) (-80) (-80) (-80) (-80)
				(-80) (-80) (-80) (-80) (-80) (-80) (-80) (-80) (-80) (-80) (-80) (-80) (-80) (-80) (-80) (-80) (-80) (-80)
				(-80) (-80) (-80) (-80) (-80) (-80) (-80) (-80) (-80) (-80) (-80) (-80) (-80) (-80) (-80) (-80) (-80) (-80)
				(-80) (-80) (-80) (-80) (-80) (-80) (-80) (-80) (-80) (-80) (-80) (-80) (-80) (-80) (-80) (-80) (-80) (-80)
				(-80) (-80) (-80) (-80) (-80) (-80) (-80) (-80) (-80) (-80) (-80) (-80) (-80) (-80) (-80) (-80) (-80) (-80)
				(-80) (-80) (-80) (-80) (-80) (-80) (-80) (-80) (-80) (-80) (-80) (-80) (-80) (-80) (-80) (-80) (-80) (-80)
				>;

			PS_Config_Lmt_FW_Diff_P = <
				75 75 75 75 75 75 75 75 75 75 75 75 75 75 75 75 75 75
				75 75 75 75 75 75 75 75 200 200 75 75 75 75 75 75 75 75
				75 75 75 75 75 75 75 75 75 75 75 75 75 75 75 75 75 75
				75 75 75 75 75 75 75 75 75 75 75 75 75 75 75 75 75 75
				75 75 75 75 75 75 75 75 75 75 75 75 75 75 75 75 75 75
				75 75 75 75 75 75 75 75 75 75 75 75 75 75 75 75 75 75
				75 75 75 75 75 75 75 75 75 75 75 75 75 75 75 75 75 75
				75 75 75 75 75 75 75 75 75 75 75 75 75 75 75 75 75 75
				75 75 75 75 75 75 75 75 75 75 75 75 75 75 75 75 75 75
				75 75 75 75 75 75 75 75 75 75 75 75 75 75 75 75 75 75
				75 75 75 75 75 75 75 75 75 75 75 75 75 75 75 75 75 75
				75 75 75 75 75 75 75 75 75 75 75 75 75 75 75 75 75 75
				75 75 75 75 75 75 75 75 75 75 75 75 75 75 75 75 75 75
				75 75 75 75 75 75 75 75 75 75 75 75 75 75 75 75 75 75
				75 75 75 75 75 75 75 75 75 75 75 75 75 75 75 75 75 75
				75 75 75 75 75 75 75 75 75 75 75 75 75 75 75 75 75 75
				75 75 75 75 75 75 75 75 75 75 75 75 75 75 75 75 75 75
				75 75 75 75 75 75 75 75 75 75 75 75 75 75 75 75 75 75
				75 75 75 75 75 75 75 75 75 75 75 75 75 75 75 75 75 75
				75 75 75 75 75 75 75 75 75 75 75 75 75 75 75 75 75 75
				75 75 75 75 75 75 75 75 75 75 75 75 75 75 75 75 75 75
				75 75 75 75 75 75 75 75 75 75 75 75 75 75 75 75 75 75
				75 75 75 75 75 75 75 75 75 75 75 75 75 75 75 75 75 75
				75 75 75 75 75 75 75 75 75 75 75 75 75 75 75 75 75 75
				75 75 75 75 75 75 75 75 75 75 75 75 75 75 75 75 75 75
				75 75 75 75 75 75 75 75 75 75 75 75 75 75 75 75 75 75
				75 75 75 75 75 75 75 75 75 75 75 75 75 75 75 75 75 75
				75 75 75 75 75 75 75 75 75 75 75 75 75 75 75 75 75 75
				75 75 75 75 75 75 75 75 75 75 75 75 75 75 75 75 75 75
				75 75 75 75 75 75 75 75 75 75 75 75 75 75 75 75 75 75
				75 75 75 75 75 75 75 75 75 75 75 75 75 75 75 75 75 75
				75 75 75 75 75 75 75 75 75 75 75 75 75 75 75 75 75 75
				75 75 75 75 75 75 75 75 75 75 75 75 75 75 75 75 75 75
				75 75 75 75 75 75 75 75 75 75 75 75 75 75 75 75 75 75
				75 75 75 75 75 75 75 75 75 75 75 75 75 75 75 75 75 75
				75 75 75 75 75 75 75 75 75 75 75 75 75 75 75 75 75 75
				75 75 75 75 75 75 75 75 75 75 75 75 75 75 75 75 75 75
				75 75 75 75 75 75 75 75 75 75 75 75 75 75 75 75 75 75
				75 75 75 75 75 75 75 75 75 75 75 75 75 75 75 75 75 75
				>;

			PS_Config_Lmt_FW_Diff_N = <
				(-75) (-75) (-75) (-75) (-75) (-75) (-75) (-75) (-75) (-75) (-75) (-75) (-75) (-75) (-75) (-75) (-75) (-75)
				(-75) (-75) (-75) (-75) (-75) (-75) (-75) (-75) (-200) (-200) (-75) (-75) (-75) (-75) (-75) (-75) (-75) (-75)
				(-75) (-75) (-75) (-75) (-75) (-75) (-75) (-75) (-75) (-75) (-75) (-75) (-75) (-75) (-75) (-75) (-75) (-75)
				(-75) (-75) (-75) (-75) (-75) (-75) (-75) (-75) (-75) (-75) (-75) (-75) (-75) (-75) (-75) (-75) (-75) (-75)
				(-75) (-75) (-75) (-75) (-75) (-75) (-75) (-75) (-75) (-75) (-75) (-75) (-75) (-75) (-75) (-75) (-75) (-75)
				(-75) (-75) (-75) (-75) (-75) (-75) (-75) (-75) (-75) (-75) (-75) (-75) (-75) (-75) (-75) (-75) (-75) (-75)
				(-75) (-75) (-75) (-75) (-75) (-75) (-75) (-75) (-75) (-75) (-75) (-75) (-75) (-75) (-75) (-75) (-75) (-75)
				(-75) (-75) (-75) (-75) (-75) (-75) (-75) (-75) (-75) (-75) (-75) (-75) (-75) (-75) (-75) (-75) (-75) (-75)
				(-75) (-75) (-75) (-75) (-75) (-75) (-75) (-75) (-75) (-75) (-75) (-75) (-75) (-75) (-75) (-75) (-75) (-75)
				(-75) (-75) (-75) (-75) (-75) (-75) (-75) (-75) (-75) (-75) (-75) (-75) (-75) (-75) (-75) (-75) (-75) (-75)
				(-75) (-75) (-75) (-75) (-75) (-75) (-75) (-75) (-75) (-75) (-75) (-75) (-75) (-75) (-75) (-75) (-75) (-75)
				(-75) (-75) (-75) (-75) (-75) (-75) (-75) (-75) (-75) (-75) (-75) (-75) (-75) (-75) (-75) (-75) (-75) (-75)
				(-75) (-75) (-75) (-75) (-75) (-75) (-75) (-75) (-75) (-75) (-75) (-75) (-75) (-75) (-75) (-75) (-75) (-75)
				(-75) (-75) (-75) (-75) (-75) (-75) (-75) (-75) (-75) (-75) (-75) (-75) (-75) (-75) (-75) (-75) (-75) (-75)
				(-75) (-75) (-75) (-75) (-75) (-75) (-75) (-75) (-75) (-75) (-75) (-75) (-75) (-75) (-75) (-75) (-75) (-75)
				(-75) (-75) (-75) (-75) (-75) (-75) (-75) (-75) (-75) (-75) (-75) (-75) (-75) (-75) (-75) (-75) (-75) (-75)
				(-75) (-75) (-75) (-75) (-75) (-75) (-75) (-75) (-75) (-75) (-75) (-75) (-75) (-75) (-75) (-75) (-75) (-75)
				(-75) (-75) (-75) (-75) (-75) (-75) (-75) (-75) (-75) (-75) (-75) (-75) (-75) (-75) (-75) (-75) (-75) (-75)
				(-75) (-75) (-75) (-75) (-75) (-75) (-75) (-75) (-75) (-75) (-75) (-75) (-75) (-75) (-75) (-75) (-75) (-75)
				(-75) (-75) (-75) (-75) (-75) (-75) (-75) (-75) (-75) (-75) (-75) (-75) (-75) (-75) (-75) (-75) (-75) (-75)
				(-75) (-75) (-75) (-75) (-75) (-75) (-75) (-75) (-75) (-75) (-75) (-75) (-75) (-75) (-75) (-75) (-75) (-75)
				(-75) (-75) (-75) (-75) (-75) (-75) (-75) (-75) (-75) (-75) (-75) (-75) (-75) (-75) (-75) (-75) (-75) (-75)
				(-75) (-75) (-75) (-75) (-75) (-75) (-75) (-75) (-75) (-75) (-75) (-75) (-75) (-75) (-75) (-75) (-75) (-75)
				(-75) (-75) (-75) (-75) (-75) (-75) (-75) (-75) (-75) (-75) (-75) (-75) (-75) (-75) (-75) (-75) (-75) (-75)
				(-75) (-75) (-75) (-75) (-75) (-75) (-75) (-75) (-75) (-75) (-75) (-75) (-75) (-75) (-75) (-75) (-75) (-75)
				(-75) (-75) (-75) (-75) (-75) (-75) (-75) (-75) (-75) (-75) (-75) (-75) (-75) (-75) (-75) (-75) (-75) (-75)
				(-75) (-75) (-75) (-75) (-75) (-75) (-75) (-75) (-75) (-75) (-75) (-75) (-75) (-75) (-75) (-75) (-75) (-75)
				(-75) (-75) (-75) (-75) (-75) (-75) (-75) (-75) (-75) (-75) (-75) (-75) (-75) (-75) (-75) (-75) (-75) (-75)
				(-75) (-75) (-75) (-75) (-75) (-75) (-75) (-75) (-75) (-75) (-75) (-75) (-75) (-75) (-75) (-75) (-75) (-75)
				(-75) (-75) (-75) (-75) (-75) (-75) (-75) (-75) (-75) (-75) (-75) (-75) (-75) (-75) (-75) (-75) (-75) (-75)
				(-75) (-75) (-75) (-75) (-75) (-75) (-75) (-75) (-75) (-75) (-75) (-75) (-75) (-75) (-75) (-75) (-75) (-75)
				(-75) (-75) (-75) (-75) (-75) (-75) (-75) (-75) (-75) (-75) (-75) (-75) (-75) (-75) (-75) (-75) (-75) (-75)
				(-75) (-75) (-75) (-75) (-75) (-75) (-75) (-75) (-75) (-75) (-75) (-75) (-75) (-75) (-75) (-75) (-75) (-75)
				(-75) (-75) (-75) (-75) (-75) (-75) (-75) (-75) (-75) (-75) (-75) (-75) (-75) (-75) (-75) (-75) (-75) (-75)
				(-75) (-75) (-75) (-75) (-75) (-75) (-75) (-75) (-75) (-75) (-75) (-75) (-75) (-75) (-75) (-75) (-75) (-75)
				(-75) (-75) (-75) (-75) (-75) (-75) (-75) (-75) (-75) (-75) (-75) (-75) (-75) (-75) (-75) (-75) (-75) (-75)
				(-75) (-75) (-75) (-75) (-75) (-75) (-75) (-75) (-75) (-75) (-75) (-75) (-75) (-75) (-75) (-75) (-75) (-75)
				(-75) (-75) (-75) (-75) (-75) (-75) (-75) (-75) (-75) (-75) (-75) (-75) (-75) (-75) (-75) (-75) (-75) (-75)
				(-75) (-75) (-75) (-75) (-75) (-75) (-75) (-75) (-75) (-75) (-75) (-75) (-75) (-75) (-75) (-75) (-75) (-75)
				>;

			PS_Config_Lmt_FW_Digital_Diff_P = <
				75 75 75 75 75 75 75 75 75 75 75 75 75 75 75 75 75 75
				75 75 75 75 75 75 75 75 200 200 75 75 75 75 75 75 75 75
				75 75 75 75 75 75 75 75 75 75 75 75 75 75 75 75 75 75
				75 75 75 75 75 75 75 75 75 75 75 75 75 75 75 75 75 75
				75 75 75 75 75 75 75 75 75 75 75 75 75 75 75 75 75 75
				75 75 75 75 75 75 75 75 75 75 75 75 75 75 75 75 75 75
				75 75 75 75 75 75 75 75 75 75 75 75 75 75 75 75 75 75
				75 75 75 75 75 75 75 75 75 75 75 75 75 75 75 75 75 75
				75 75 75 75 75 75 75 75 75 75 75 75 75 75 75 75 75 75
				75 75 75 75 75 75 75 75 75 75 75 75 75 75 75 75 75 75
				75 75 75 75 75 75 75 75 75 75 75 75 75 75 75 75 75 75
				75 75 75 75 75 75 75 75 75 75 75 75 75 75 75 75 75 75
				75 75 75 75 75 75 75 75 75 75 75 75 75 75 75 75 75 75
				75 75 75 75 75 75 75 75 75 75 75 75 75 75 75 75 75 75
				75 75 75 75 75 75 75 75 75 75 75 75 75 75 75 75 75 75
				75 75 75 75 75 75 75 75 75 75 75 75 75 75 75 75 75 75
				75 75 75 75 75 75 75 75 75 75 75 75 75 75 75 75 75 75
				75 75 75 75 75 75 75 75 75 75 75 75 75 75 75 75 75 75
				75 75 75 75 75 75 75 75 75 75 75 75 75 75 75 75 75 75
				75 75 75 75 75 75 75 75 75 75 75 75 75 75 75 75 75 75
				75 75 75 75 75 75 75 75 75 75 75 75 75 75 75 75 75 75
				75 75 75 75 75 75 75 75 75 75 75 75 75 75 75 75 75 75
				75 75 75 75 75 75 75 75 75 75 75 75 75 75 75 75 75 75
				75 75 75 75 75 75 75 75 75 75 75 75 75 75 75 75 75 75
				75 75 75 75 75 75 75 75 75 75 75 75 75 75 75 75 75 75
				75 75 75 75 75 75 75 75 75 75 75 75 75 75 75 75 75 75
				75 75 75 75 75 75 75 75 75 75 75 75 75 75 75 75 75 75
				75 75 75 75 75 75 75 75 75 75 75 75 75 75 75 75 75 75
				75 75 75 75 75 75 75 75 75 75 75 75 75 75 75 75 75 75
				75 75 75 75 75 75 75 75 75 75 75 75 75 75 75 75 75 75
				75 75 75 75 75 75 75 75 75 75 75 75 75 75 75 75 75 75
				75 75 75 75 75 75 75 75 75 75 75 75 75 75 75 75 75 75
				75 75 75 75 75 75 75 75 75 75 75 75 75 75 75 75 75 75
				75 75 75 75 75 75 75 75 75 75 75 75 75 75 75 75 75 75
				75 75 75 75 75 75 75 75 75 75 75 75 75 75 75 75 75 75
				75 75 75 75 75 75 75 75 75 75 75 75 75 75 75 75 75 75
				75 75 75 75 75 75 75 75 75 75 75 75 75 75 75 75 75 75
				75 75 75 75 75 75 75 75 75 75 75 75 75 75 75 75 75 75
				75 75 75 75 75 75 75 75 75 75 75 75 75 75 75 75 75 75
				>;

			PS_Config_Lmt_FW_Digital_Diff_N = <
				(-75) (-75) (-75) (-75) (-75) (-75) (-75) (-75) (-75) (-75) (-75) (-75) (-75) (-75) (-75) (-75) (-75) (-75)
				(-75) (-75) (-75) (-75) (-75) (-75) (-75) (-75) (-200) (-200) (-75) (-75) (-75) (-75) (-75) (-75) (-75) (-75)
				(-75) (-75) (-75) (-75) (-75) (-75) (-75) (-75) (-75) (-75) (-75) (-75) (-75) (-75) (-75) (-75) (-75) (-75)
				(-75) (-75) (-75) (-75) (-75) (-75) (-75) (-75) (-75) (-75) (-75) (-75) (-75) (-75) (-75) (-75) (-75) (-75)
				(-75) (-75) (-75) (-75) (-75) (-75) (-75) (-75) (-75) (-75) (-75) (-75) (-75) (-75) (-75) (-75) (-75) (-75)
				(-75) (-75) (-75) (-75) (-75) (-75) (-75) (-75) (-75) (-75) (-75) (-75) (-75) (-75) (-75) (-75) (-75) (-75)
				(-75) (-75) (-75) (-75) (-75) (-75) (-75) (-75) (-75) (-75) (-75) (-75) (-75) (-75) (-75) (-75) (-75) (-75)
				(-75) (-75) (-75) (-75) (-75) (-75) (-75) (-75) (-75) (-75) (-75) (-75) (-75) (-75) (-75) (-75) (-75) (-75)
				(-75) (-75) (-75) (-75) (-75) (-75) (-75) (-75) (-75) (-75) (-75) (-75) (-75) (-75) (-75) (-75) (-75) (-75)
				(-75) (-75) (-75) (-75) (-75) (-75) (-75) (-75) (-75) (-75) (-75) (-75) (-75) (-75) (-75) (-75) (-75) (-75)
				(-75) (-75) (-75) (-75) (-75) (-75) (-75) (-75) (-75) (-75) (-75) (-75) (-75) (-75) (-75) (-75) (-75) (-75)
				(-75) (-75) (-75) (-75) (-75) (-75) (-75) (-75) (-75) (-75) (-75) (-75) (-75) (-75) (-75) (-75) (-75) (-75)
				(-75) (-75) (-75) (-75) (-75) (-75) (-75) (-75) (-75) (-75) (-75) (-75) (-75) (-75) (-75) (-75) (-75) (-75)
				(-75) (-75) (-75) (-75) (-75) (-75) (-75) (-75) (-75) (-75) (-75) (-75) (-75) (-75) (-75) (-75) (-75) (-75)
				(-75) (-75) (-75) (-75) (-75) (-75) (-75) (-75) (-75) (-75) (-75) (-75) (-75) (-75) (-75) (-75) (-75) (-75)
				(-75) (-75) (-75) (-75) (-75) (-75) (-75) (-75) (-75) (-75) (-75) (-75) (-75) (-75) (-75) (-75) (-75) (-75)
				(-75) (-75) (-75) (-75) (-75) (-75) (-75) (-75) (-75) (-75) (-75) (-75) (-75) (-75) (-75) (-75) (-75) (-75)
				(-75) (-75) (-75) (-75) (-75) (-75) (-75) (-75) (-75) (-75) (-75) (-75) (-75) (-75) (-75) (-75) (-75) (-75)
				(-75) (-75) (-75) (-75) (-75) (-75) (-75) (-75) (-75) (-75) (-75) (-75) (-75) (-75) (-75) (-75) (-75) (-75)
				(-75) (-75) (-75) (-75) (-75) (-75) (-75) (-75) (-75) (-75) (-75) (-75) (-75) (-75) (-75) (-75) (-75) (-75)
				(-75) (-75) (-75) (-75) (-75) (-75) (-75) (-75) (-75) (-75) (-75) (-75) (-75) (-75) (-75) (-75) (-75) (-75)
				(-75) (-75) (-75) (-75) (-75) (-75) (-75) (-75) (-75) (-75) (-75) (-75) (-75) (-75) (-75) (-75) (-75) (-75)
				(-75) (-75) (-75) (-75) (-75) (-75) (-75) (-75) (-75) (-75) (-75) (-75) (-75) (-75) (-75) (-75) (-75) (-75)
				(-75) (-75) (-75) (-75) (-75) (-75) (-75) (-75) (-75) (-75) (-75) (-75) (-75) (-75) (-75) (-75) (-75) (-75)
				(-75) (-75) (-75) (-75) (-75) (-75) (-75) (-75) (-75) (-75) (-75) (-75) (-75) (-75) (-75) (-75) (-75) (-75)
				(-75) (-75) (-75) (-75) (-75) (-75) (-75) (-75) (-75) (-75) (-75) (-75) (-75) (-75) (-75) (-75) (-75) (-75)
				(-75) (-75) (-75) (-75) (-75) (-75) (-75) (-75) (-75) (-75) (-75) (-75) (-75) (-75) (-75) (-75) (-75) (-75)
				(-75) (-75) (-75) (-75) (-75) (-75) (-75) (-75) (-75) (-75) (-75) (-75) (-75) (-75) (-75) (-75) (-75) (-75)
				(-75) (-75) (-75) (-75) (-75) (-75) (-75) (-75) (-75) (-75) (-75) (-75) (-75) (-75) (-75) (-75) (-75) (-75)
				(-75) (-75) (-75) (-75) (-75) (-75) (-75) (-75) (-75) (-75) (-75) (-75) (-75) (-75) (-75) (-75) (-75) (-75)
				(-75) (-75) (-75) (-75) (-75) (-75) (-75) (-75) (-75) (-75) (-75) (-75) (-75) (-75) (-75) (-75) (-75) (-75)
				(-75) (-75) (-75) (-75) (-75) (-75) (-75) (-75) (-75) (-75) (-75) (-75) (-75) (-75) (-75) (-75) (-75) (-75)
				(-75) (-75) (-75) (-75) (-75) (-75) (-75) (-75) (-75) (-75) (-75) (-75) (-75) (-75) (-75) (-75) (-75) (-75)
				(-75) (-75) (-75) (-75) (-75) (-75) (-75) (-75) (-75) (-75) (-75) (-75) (-75) (-75) (-75) (-75) (-75) (-75)
				(-75) (-75) (-75) (-75) (-75) (-75) (-75) (-75) (-75) (-75) (-75) (-75) (-75) (-75) (-75) (-75) (-75) (-75)
				(-75) (-75) (-75) (-75) (-75) (-75) (-75) (-75) (-75) (-75) (-75) (-75) (-75) (-75) (-75) (-75) (-75) (-75)
				(-75) (-75) (-75) (-75) (-75) (-75) (-75) (-75) (-75) (-75) (-75) (-75) (-75) (-75) (-75) (-75) (-75) (-75)
				(-75) (-75) (-75) (-75) (-75) (-75) (-75) (-75) (-75) (-75) (-75) (-75) (-75) (-75) (-75) (-75) (-75) (-75)
				(-75) (-75) (-75) (-75) (-75) (-75) (-75) (-75) (-75) (-75) (-75) (-75) (-75) (-75) (-75) (-75) (-75) (-75)
				>;

			PS_Config_Diff_Test_Frame = <50>;
			PS_Config_Digital_Diff_Test_Frame = <50>;
		};
	};
};

&pmxr2230_gpios {
    xo_therm {
            xo_therm_default: xo_therm_default {
            pins = "gpio10";
            bias-high-impedance;
            };
    };

	conn_therm2 {
		conn_therm2_default: conn_therm2_default {
		pins = "gpio7";
		bias-high-impedance;
		};
	};
};

&pm7550ba_gpios {
	wifi_therm {
		wifi_therm_default: wifi_therm_default {
		pins = "gpio3";
		bias-high-impedance;
		};
	};

	display_therm {
		display_therm_default: display_therm_default {
		pins = "gpio4";
		bias-high-impedance;
		};
	};

	charger_therm {
		charger_therm_default: charger_therm_default {
		pins = "gpio6";
		bias-high-impedance;
		};
	};
};

&pmk8550_vadc {
	pinctrl-names = "default";
	pinctrl-0 =<&xo_therm_default>,<&conn_therm2_default>,<&wifi_therm_default>,<&display_therm_default>,<&charger_therm_default>;
	pmxr2230_xo_therm {
		reg = <PMXR2230_ADC5_GEN3_AMUX4_GPIO10_100K_PU>;
		label = "pmxr2230_xo_therm";
		qcom,ratiometric;
		qcom,hw-settle-time = <200>;
		qcom,pre-scaling = <1 1>;
		qcom,adc-tm-type = <1>;
	};

	pmxr2230_pa_therm0 {
		reg = <PMXR2230_ADC5_GEN3_AMUX_THM1_100K_PU>;
		label = "pmxr2230_pa_therm0";
		qcom,ratiometric;
		qcom,hw-settle-time = <200>;
		qcom,pre-scaling = <1 1>;
		qcom,adc-tm-type = <1>;
	};

	pmxr2230_cpu_therm {
		reg = <PMXR2230_ADC5_GEN3_AMUX_THM2_100K_PU>;
		label = "pmxr2230_cpu_therm";
		qcom,ratiometric;
		qcom,hw-settle-time = <200>;
		qcom,pre-scaling = <1 1>;
		qcom,adc-tm-type = <1>;
	};

	pmxr2230_pa_therm1 {
		reg = <PMXR2230_ADC5_GEN3_AMUX_THM3_100K_PU>;
		label = "pmxr2230_pa_therm1";
		qcom,ratiometric;
		qcom,hw-settle-time = <200>;
		qcom,pre-scaling = <1 1>;
		qcom,adc-tm-type = <1>;
	};

	pmxr2230_quiet_therm {
		reg = <PMXR2230_ADC5_GEN3_AMUX_THM4_100K_PU>;
		label = "pmxr2230_quiet_therm";
		qcom,ratiometric;
		qcom,hw-settle-time = <200>;
		qcom,pre-scaling = <1 1>;
		qcom,adc-tm-type = <1>;
	};

	pmxr2230_flash_therm {
		reg = <PMXR2230_ADC5_GEN3_AMUX_THM5_100K_PU>;
		label = "pmxr2230_flash_therm";
		qcom,ratiometric;
		qcom,hw-settle-time = <200>;
		qcom,pre-scaling = <1 1>;
		qcom,adc-tm-type = <1>;
	};

	pmxr2230_conn_therm2 {
		reg = <PMXR2230_ADC5_GEN3_AMUX3_GPIO7_100K_PU>;
		label = "pmxr2230_conn_therm2";
		qcom,ratiometric;
		qcom,pre-scaling = <1 1>;
		qcom,adc-tm-type = <1>;
	};

	pm7550ba_wifi_therm {
		reg = <PM7550BA_ADC5_GEN3_AMUX3_GPIO3_100K_PU>;
		label = "pm7550ba_wifi_therm";
		qcom,ratiometric;
		qcom,pre-scaling = <1 1>;
		qcom,adc-tm-type = <1>;
	};

	pm7550ba_display_therm {
		reg = <PM7550BA_ADC5_GEN3_AMUX4_GPIO4_100K_PU>;
		label = "pm7550ba_display_therm";
		qcom,ratiometric;
		qcom,pre-scaling = <1 1>;
		qcom,adc-tm-type = <1>;
	};

	pm7550ba_charger_therm {
		reg = <PM7550BA_ADC5_GEN3_AMUX_THM6_GPIO6_100K_PU>;
		label = "pm7550ba_charger_therm";
		qcom,ratiometric;
		qcom,pre-scaling = <1 1>;
		qcom,adc-tm-type = <1>;
	};

	pm7550ba_batt_therm {
		reg = <PM7550BA_ADC5_GEN3_AMUX_THM1_BATT_THERM_100K_PU>;
		label = "pm7550ba_batt_therm";
		qcom,ratiometric;
		qcom,pre-scaling = <1 1>;
		qcom,adc-tm-type = <1>;
	};

	pm7550ba_conn_therm {
		reg = <PM7550BA_ADC5_GEN3_AMUX_THM4_USB_THERM_100K_PU>;
		label = "pm7550ba_conn_therm";
		qcom,ratiometric;
		qcom,pre-scaling = <1 1>;
		qcom,adc-tm-type = <1>;
	};
};

&thermal_zones {
	xo_therm {
		polling-delay-passive = <0>;
		polling-delay = <0>;
		thermal-sensors = <&pmk8550_vadc PMXR2230_ADC5_GEN3_AMUX4_GPIO10_100K_PU>;
		trips {
			active-config0 {
				temperature = <125000>;
				hysteresis = <1000>;
				type = "passive";
			};
			active-config1 {
				temperature = <125000>;
				hysteresis = <1000>;
				type = "passive";
			};
		};
	};

	pa_therm0 {
		polling-delay-passive = <0>;
		polling-delay = <0>;
		thermal-sensors = <&pmk8550_vadc PMXR2230_ADC5_GEN3_AMUX_THM1_100K_PU>;
		trips {
			active-config0 {
				temperature = <125000>;
				hysteresis = <1000>;
				type = "passive";
			};
			active-config1 {
				temperature = <125000>;
				hysteresis = <1000>;
				type = "passive";
			};
		};
	};

	cpu_therm {
		polling-delay-passive = <0>;
		polling-delay = <0>;
		thermal-sensors = <&pmk8550_vadc PMXR2230_ADC5_GEN3_AMUX_THM2_100K_PU>;
		trips {
			active-config0 {
				temperature = <125000>;
				hysteresis = <1000>;
				type = "passive";
			};
			active-config1 {
				temperature = <125000>;
				hysteresis = <1000>;
				type = "passive";
			};
		};
	};

	pa_therm1 {
		polling-delay-passive = <0>;
		polling-delay = <0>;
		thermal-sensors = <&pmk8550_vadc PMXR2230_ADC5_GEN3_AMUX_THM3_100K_PU>;
		trips {
			active-config0 {
				temperature = <125000>;
				hysteresis = <1000>;
				type = "passive";
			};
			active-config1 {
				temperature = <125000>;
				hysteresis = <1000>;
				type = "passive";
			};
		};
	};

	quiet_therm {
		polling-delay-passive = <0>;
		polling-delay = <0>;
		thermal-sensors = <&pmk8550_vadc PMXR2230_ADC5_GEN3_AMUX_THM4_100K_PU>;
		trips {
			active-config0 {
				temperature = <125000>;
				hysteresis = <1000>;
				type = "passive";
			};
			active-config1 {
				temperature = <125000>;
				hysteresis = <1000>;
				type = "passive";
			};
		};
	};

	flash_therm {
		polling-delay-passive = <0>;
		polling-delay = <0>;
		thermal-sensors = <&pmk8550_vadc PMXR2230_ADC5_GEN3_AMUX_THM5_100K_PU>;
		trips {
			active-config0 {
				temperature = <125000>;
				hysteresis = <1000>;
				type = "passive";
			};
			active-config1 {
				temperature = <125000>;
				hysteresis = <1000>;
				type = "passive";
			};
		};
	};

	conn_therm2 {
		polling-delay-passive = <0>;
		polling-delay = <0>;
		thermal-sensors = <&pmk8550_vadc PMXR2230_ADC5_GEN3_AMUX3_GPIO7_100K_PU>;
		trips {
			active-config0 {
				temperature = <125000>;
				hysteresis = <1000>;
				type = "passive";
			};
			active-config1 {
				temperature = <125000>;
				hysteresis = <1000>;
				type = "passive";
			};
		};
	};

	wifi_therm {
		polling-delay-passive = <0>;
		polling-delay = <0>;
		thermal-sensors = <&pmk8550_vadc PM7550BA_ADC5_GEN3_AMUX3_GPIO3_100K_PU>;
		trips {
			active-config0 {
				temperature = <125000>;
				hysteresis = <1000>;
				type = "passive";
			};
			active-config1 {
				temperature = <125000>;
				hysteresis = <1000>;
				type = "passive";
			};
		};
	};

	display_therm {
		polling-delay-passive = <0>;
		polling-delay = <0>;
		thermal-sensors = <&pmk8550_vadc PM7550BA_ADC5_GEN3_AMUX4_GPIO4_100K_PU>;
		trips {
			active-config0 {
				temperature = <125000>;
				hysteresis = <1000>;
				type = "passive";
			};
			active-config1 {
				temperature = <125000>;
				hysteresis = <1000>;
				type = "passive";
			};
		};
	};

	charger_therm {
		polling-delay-passive = <0>;
		polling-delay = <0>;
		thermal-sensors = <&pmk8550_vadc PM7550BA_ADC5_GEN3_AMUX_THM6_GPIO6_100K_PU>;
		trips {
			active-config0 {
				temperature = <125000>;
				hysteresis = <1000>;
				type = "passive";
			};
			active-config1 {
				temperature = <125000>;
				hysteresis = <1000>;
				type = "passive";
			};
		};
	};

	batt_therm {
		polling-delay-passive = <0>;
		polling-delay = <0>;
		thermal-sensors = <&pmk8550_vadc PM7550BA_ADC5_GEN3_AMUX_THM1_BATT_THERM_100K_PU>;
		trips {
			active-config0 {
				temperature = <125000>;
				hysteresis = <1000>;
				type = "passive";
			};
			active-config1 {
				temperature = <125000>;
				hysteresis = <1000>;
				type = "passive";
			};
		};
	};

	conn_therm {
		polling-delay-passive = <0>;
		polling-delay = <0>;
		thermal-sensors = <&pmk8550_vadc PM7550BA_ADC5_GEN3_AMUX_THM4_USB_THERM_100K_PU>;
		trips {
			active-config0 {
				temperature = <125000>;
				hysteresis = <1000>;
				type = "passive";
			};
			active-config1 {
				temperature = <125000>;
				hysteresis = <1000>;
				type = "passive";
			};
		};
	};
};

/*Start Remove pm8010_m  pmic*/
&pm8010_m {
	status = "disabled";

};
/*End Remove pm8010_m  pmic*/
